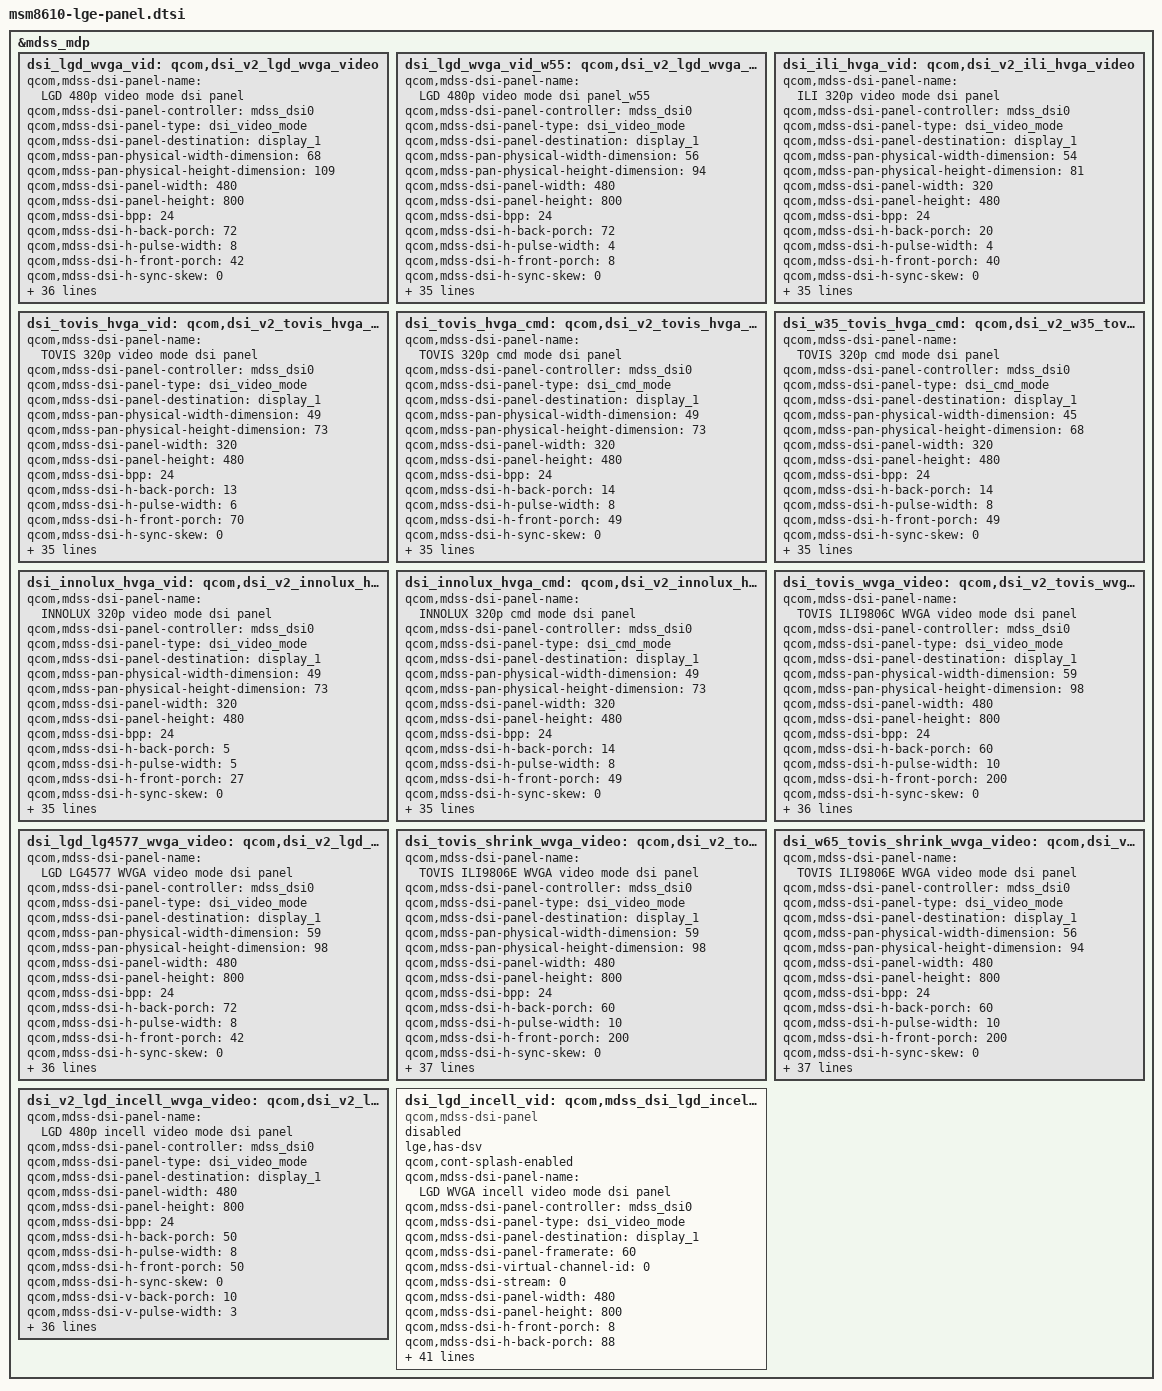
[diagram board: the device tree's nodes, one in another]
/* Copyright (c) 2012, Code Aurora Forum. All rights reserved.
 *
 * This program is free software; you can redistribute it and/or modify
 * it under the terms of the GNU General Public License version 2 and
 * only version 2 as published by the Free Software Foundation.
 *
 * This program is distributed in the hope that it will be useful,
 * but WITHOUT ANY WARRANTY; without even the implied warranty of
 * MERCHANTABILITY or FITNESS FOR A PARTICULAR PURPOSE.  See the
 * GNU General Public License for more details.
 */

&mdss_mdp {
	/* W6DS display - LGD 4573B */
	dsi_lgd_wvga_vid: qcom,dsi_v2_lgd_wvga_video {
		qcom,mdss-dsi-panel-name = "LGD 480p video mode dsi panel";
		qcom,mdss-dsi-panel-controller = <&mdss_dsi0>;
		qcom,mdss-dsi-panel-type = "dsi_video_mode";
		qcom,mdss-dsi-panel-destination = "display_1";
    qcom,mdss-pan-physical-width-dimension = <68>;
    qcom,mdss-pan-physical-height-dimension = <109>;
		qcom,mdss-dsi-panel-width = <480>;
		qcom,mdss-dsi-panel-height = <800>;
		qcom,mdss-dsi-bpp = <24>;
		qcom,mdss-dsi-h-back-porch = <72>;
		qcom,mdss-dsi-h-pulse-width = <8>;
		qcom,mdss-dsi-h-front-porch = <42>;
		qcom,mdss-dsi-h-sync-skew = <0>;
		qcom,mdss-dsi-v-back-porch = <16>;
		qcom,mdss-dsi-v-pulse-width = <10>;
		qcom,mdss-dsi-v-front-porch = <8>;
		qcom,mdss-dsi-underflow-color = <0xff>;
		qcom,mdss-dsi-bl-min-level = <1>;
		qcom,mdss-dsi-bl-max-level = <255>;
		qcom,mdss-dsi-bl-pmic-control-type = "bl_ctrl_wled";
		qcom,mdss-dsi-h-sync-pulse = <1>;
		qcom,mdss-dsi-hfp-power-mode;
		qcom,mdss-dsi-hbp-power-mode;
		qcom,mdss-dsi-hsa-power-mode;
		qcom,mdss-dsi-bllp-eof-power-mode;
		qcom,mdss-dsi-bllp-power-mode;
		qcom,mdss-dsi-traffic-mode = "non_burst_sync_event";
		qcom,mdss-dsi-virtual-channel-id = <0>;
		qcom,mdss-dsi-color-order = "rgb_swap_rgb";
		qcom,mdss-dsi-lane-0-state;
		qcom,mdss-dsi-lane-1-state;
		qcom,mdss-dsi-lane-map = "lane_map_3012";
		qcom,mdss-dsi-t-clk-pre = <0x2D>;
		qcom,mdss-dsi-t-clk-post = <0x19>;
		qcom,mdss-dsi-stream = <0>;
		qcom,mdss-dsi-mdp-trigger = "none";
		qcom,mdss-dsi-dma-trigger = "trigger_sw";
		qcom,mdss-dsi-panel-framerate = <60>;
		qcom,mdss-dsi-panel-timings = [A9 8A 16 00 91 93 1A 8C 11 03 04 00];
		qcom,mdss-dsi-on-command-state = "dsi_lp_mode";
		qcom,mdss-dsi-off-command-state = "dsi_lp_mode";
		qcom,mdss-dsi-reset-sequence = <1 1>, <0 1>, <1 10>;
		qcom,mdss-dsi-on-command = [
				05 01 00 00 00 00 01
				  20
				15 01 00 00 00 00 02
				  36 03
				15 01 00 00 00 00 02
				  3A 70
				39 01 00 00 00 00 04
				  B1 06 43 0A
				39 01 00 00 00 00 03
				  B2 20 C8
				39 01 00 00 00 00 02
				  B3 00
				39 01 00 00 00 00 02
				  B4 04
				39 01 00 00 00 00 06
				  B5 40 10 10 00 00
				39 01 00 00 00 00 07
				  B6 03 3F 02 40 3F E8
				39 01 00 00 00 00 06
				  C3 07 0A 0A 0A 02
				39 01 00 00 00 00 07
				  C4 12 24 18 18 01 49
				39 01 00 00 00 00 02
				  C5 74
				39 01 00 00 00 00 04
				  C6 41 63 03
				39 01 00 00 00 00 0A
				  D0 00 55 67 02 01 00 31 02 02
				39 01 00 00 00 00 0A
				  D1 00 55 67 02 01 00 31 02 02
				39 01 00 00 00 00 0A
				  D2 00 55 67 02 01 00 31 02 02
				39 01 00 00 00 00 0A
				  D3 00 55 67 02 01 00 31 02 02
				39 01 00 00 00 00 0A
				  D4 00 55 67 02 01 00 31 02 02
				39 01 00 00 00 00 0A
				  D5 00 55 67 02 01 00 31 02 02
				05 01 00 00 78 00 01
				  11
				05 01 00 00 28 00 01
				  29
		];
		qcom,mdss-dsi-off-command = [
				05 01 00 00 28 00 01
				  28
				05 01 00 00 3C 00 01
				  10
		];
	};
	dsi_lgd_wvga_vid_w55: qcom,dsi_v2_lgd_wvga_video_w55 {
		qcom,mdss-dsi-panel-name = "LGD 480p video mode dsi panel_w55";
		qcom,mdss-dsi-panel-controller = <&mdss_dsi0>;
		qcom,mdss-dsi-panel-type = "dsi_video_mode";
		qcom,mdss-dsi-panel-destination = "display_1";
		qcom,mdss-pan-physical-width-dimension = <56>;
		qcom,mdss-pan-physical-height-dimension = <94>;
		qcom,mdss-dsi-panel-width = <480>;
		qcom,mdss-dsi-panel-height = <800>;
		qcom,mdss-dsi-bpp = <24>;
		qcom,mdss-dsi-h-back-porch = <72>;
		qcom,mdss-dsi-h-pulse-width = <4>;
		qcom,mdss-dsi-h-front-porch = <8>;
		qcom,mdss-dsi-h-sync-skew = <0>;
		qcom,mdss-dsi-v-back-porch = <16>;
		qcom,mdss-dsi-v-pulse-width = <1>;
		qcom,mdss-dsi-v-front-porch = <8>;
		qcom,mdss-dsi-underflow-color = <0xff>;
		qcom,mdss-dsi-bl-min-level = <1>;
		qcom,mdss-dsi-bl-max-level = <255>;
		qcom,mdss-dsi-bl-pmic-control-type = "bl_ctrl_wled";
		qcom,mdss-dsi-h-sync-pulse = <1>;
		qcom,mdss-dsi-hfp-power-mode;
		qcom,mdss-dsi-hbp-power-mode;
		qcom,mdss-dsi-hsa-power-mode;
		qcom,mdss-dsi-bllp-eof-power-mode;
		qcom,mdss-dsi-bllp-power-mode;
		qcom,mdss-dsi-traffic-mode = "non_burst_sync_event";
		qcom,mdss-dsi-virtual-channel-id = <0>;
		qcom,mdss-dsi-color-order = "rgb_swap_rgb";
		qcom,mdss-dsi-lane-0-state;
		qcom,mdss-dsi-lane-1-state;
		qcom,mdss-dsi-lane-map = "lane_map_3012";
		qcom,mdss-dsi-t-clk-pre = <0x2D>;
		qcom,mdss-dsi-t-clk-post = <0x19>;
		qcom,mdss-dsi-stream = <0>;
		qcom,mdss-dsi-mdp-trigger = "none";
		qcom,mdss-dsi-dma-trigger = "trigger_sw";
		qcom,mdss-dsi-panel-framerate = <60>;
		qcom,mdss-dsi-panel-timings = [A5 89 15 00 8F 8F 18 8B 0F 03 04 00];
		qcom,mdss-dsi-on-command-state = "dsi_lp_mode";
		qcom,mdss-dsi-off-command-state = "dsi_lp_mode";
		qcom,mdss-dsi-on-command = [
				05 01 00 00 00 00 01
				  20
				15 01 00 00 00 00 02
				  36 00
				15 01 00 00 00 00 02
				  3A 70
				39 01 00 00 00 00 04
				  B1 06 43 0A
				39 01 00 00 00 00 03
				  B2 00 C8
				39 01 00 00 00 00 02
				  B3 02
				39 01 00 00 00 00 02
				  B4 00
				39 01 00 00 00 00 06
				  B5 40 10 10 00 00
				39 01 00 00 00 00 07
				  B6 0B 0F 02 40 10 E8
				39 01 00 00 00 00 06
				  C3 07 0A 0A 0A 02
				39 01 00 00 00 00 07
				  C4 12 24 18 18 02 49
				39 01 00 00 00 00 02
				  C5 69
				39 01 00 00 00 00 04
				  C6 41 63 03
				39 01 00 00 00 00 0A
				  D0 10 76 54 02 00 00 31 03 02
				39 01 00 00 00 00 0A
				  D1 10 76 54 02 00 00 31 03 02
				39 01 00 00 00 00 0A
				  D2 10 76 54 02 00 00 31 03 02
				39 01 00 00 00 00 0A
				  D3 10 76 54 02 00 00 31 03 02
				39 01 00 00 00 00 0A
				  D4 10 76 54 02 00 00 31 03 02
				39 01 00 00 00 00 0A
				  D5 10 76 54 02 00 00 31 03 02
				05 01 00 00 78 00 01
				  11
				05 01 00 00 28 00 01
				  29
		];
		qcom,mdss-dsi-off-command = [
				05 01 00 00 28 00 01
				  28
				05 01 00 00 0A 00 01
				  10
		];
	};
	dsi_ili_hvga_vid: qcom,dsi_v2_ili_hvga_video {
		qcom,mdss-dsi-panel-name = "ILI 320p video mode dsi panel";
		qcom,mdss-dsi-panel-controller = <&mdss_dsi0>;
		qcom,mdss-dsi-panel-type = "dsi_video_mode";
		qcom,mdss-dsi-panel-destination = "display_1";
		qcom,mdss-pan-physical-width-dimension = <54>;
		qcom,mdss-pan-physical-height-dimension = <81>;
		qcom,mdss-dsi-panel-width = <320>;
		qcom,mdss-dsi-panel-height = <480>;
		qcom,mdss-dsi-bpp = <24>;
		qcom,mdss-dsi-h-back-porch = <20>;
		qcom,mdss-dsi-h-pulse-width = <4>;
		qcom,mdss-dsi-h-front-porch = <40>;
		qcom,mdss-dsi-h-sync-skew = <0>;
		qcom,mdss-dsi-v-back-porch = <8>;
		qcom,mdss-dsi-v-pulse-width = <4>;
		qcom,mdss-dsi-v-front-porch = <8>;
		qcom,mdss-dsi-underflow-color = <0xff>;
		qcom,mdss-dsi-bl-min-level = <1>;
		qcom,mdss-dsi-bl-max-level = <255>;
		qcom,mdss-dsi-bl-pmic-control-type = "bl_ctrl_wled";
		qcom,mdss-dsi-h-sync-pulse = <0>;
		qcom,mdss-dsi-traffic-mode = "non_burst_sync_event";
		qcom,mdss-dsi-bllp-eof-power-mode;
		qcom,mdss-dsi-bllp-power-mode;
		qcom,mdss-dsi-te-dcs-command = <1>;
		qcom,mdss-dsi-te-v-sync-rd-ptr-irq-line = <0x2c>;
		qcom,mdss-dsi-te-v-sync-continues-lines = <0x3c>;
		qcom,mdss-dsi-virtual-channel-id = <0>;
		qcom,mdss-dsi-color-order = "rgb_swap_rgb";
		qcom,mdss-dsi-lane-0-state;
		qcom,mdss-dsi-lane-map = "lane_map_3012";
		qcom,mdss-dsi-t-clk-pre = <0x2C>;
		qcom,mdss-dsi-t-clk-post = <0x19>;
		qcom,mdss-dsi-stream = <0>;
		qcom,mdss-dsi-mdp-trigger = "trigger_te";
		qcom,mdss-dsi-dma-trigger = "trigger_sw";
		qcom,mdss-dsi-panel-framerate = <60>;
		qcom,mdss-dsi-panel-timings = [9F 87 10 00 8D 8E 14 89 0C 03 04 00];
		qcom,mdss-dsi-on-command-state = "dsi_lp_mode";
		qcom,mdss-dsi-off-command-state = "dsi_lp_mode";
		qcom,mdss-dsi-reset-sequence = <1 2>, <0 10>, <1 120>;
		qcom,mdss-dsi-on-command = [
				23 01 00 00 00 00 02
				  C1 41
				23 01 00 00 00 00 04
				  C0 0C 0C FF
				29 01 00 00 00 00 10
				  E0 00 11 13 05 10 06 3C
				  88 54 0A 0D 0B 30 36 0F
				29 01 00 00 00 00 10
				  E1 00 07 0D 04 12 04 29
				  44 42 09 0F 0A 2B 2D 0F
				29 01 00 00 00 00 04
				  C5 00 60 80
				39 01 00 00 00 00 03
				  B1 C0 15
				29 01 00 00 00 00 05
				  B5 0F 0F 0C 2A
				23 01 00 00 00 00 02
				  B4 20
				29 01 00 00 00 00 04
				  B6 82 42 3B
				23 01 00 00 00 00 02
				  E9 00
				39 01 00 00 00 00 06
				  F2 58 10 12 02 92
				39 01 00 00 00 00 05
				  F7 A9 51 2C 82
				15 01 00 00 00 00 02
				  3A 77
				05 01 00 00 00 00 02
				  21 00
				15 01 00 00 00 00 02
				  36 08
				05 01 00 00 78 00 01
				  11
				05 01 00 00 00 00 01
				  29
				05 01 00 00 50 00 01
				  2C
				];
		qcom,mdss-dsi-off-command = [
				05 01 00 00 32 00 01
				  28
				05 01 00 00 78 00 01
				  10
				];
	};
	dsi_tovis_hvga_vid: qcom,dsi_v2_tovis_hvga_video {
		qcom,mdss-dsi-panel-name = "TOVIS 320p video mode dsi panel";
		qcom,mdss-dsi-panel-controller = <&mdss_dsi0>;
		qcom,mdss-dsi-panel-type = "dsi_video_mode";
		qcom,mdss-dsi-panel-destination = "display_1";
		qcom,mdss-pan-physical-width-dimension = <49>;
		qcom,mdss-pan-physical-height-dimension = <73>;
		qcom,mdss-dsi-panel-width = <320>;
		qcom,mdss-dsi-panel-height = <480>;
		qcom,mdss-dsi-bpp = <24>;
		qcom,mdss-dsi-h-back-porch = <13>;
		qcom,mdss-dsi-h-pulse-width = <6>;
		qcom,mdss-dsi-h-front-porch = <70>;
		qcom,mdss-dsi-h-sync-skew = <0>;
		qcom,mdss-dsi-v-back-porch = <3>;
		qcom,mdss-dsi-v-pulse-width = <3>;
		qcom,mdss-dsi-v-front-porch = <3>;
		qcom,mdss-dsi-underflow-color = <0xff>;
		qcom,mdss-dsi-bl-min-level = <1>;
		qcom,mdss-dsi-bl-max-level = <255>;
		qcom,mdss-dsi-bl-pmic-control-type = "bl_ctrl_wled";
		qcom,mdss-dsi-h-sync-pulse = <0>;
		qcom,mdss-dsi-traffic-mode = "non_burst_sync_event";
		qcom,mdss-dsi-bllp-eof-power-mode;
		qcom,mdss-dsi-bllp-power-mode;
		qcom,mdss-dsi-te-dcs-command = <1>;
		qcom,mdss-dsi-te-v-sync-rd-ptr-irq-line = <0x2c>;
		qcom,mdss-dsi-te-v-sync-continues-lines = <0x3c>;
		qcom,mdss-dsi-virtual-channel-id = <0>;
		qcom,mdss-dsi-color-order = "rgb_swap_rgb";
		qcom,mdss-dsi-lane-0-state;
		qcom,mdss-dsi-lane-map = "lane_map_3012";
		qcom,mdss-dsi-t-clk-pre = <0x27>;
		qcom,mdss-dsi-t-clk-post = <0x20>;
		qcom,mdss-dsi-stream = <0>;
		qcom,mdss-dsi-mdp-trigger = "trigger_te";
		qcom,mdss-dsi-dma-trigger = "trigger_sw";
		qcom,mdss-dsi-panel-framerate = <60>;
		qcom,mdss-dsi-panel-timings = [45 16 0D 00 22 23 11 18 16 03 04 00];
		qcom,mdss-dsi-on-command-state = "dsi_lp_mode";
		qcom,mdss-dsi-off-command-state = "dsi_lp_mode";
		qcom,mdss-dsi-reset-sequence = <1 2>, <0 10>, <1 120>;
		qcom,mdss-dsi-on-command = [
				29 01 00 00 00 00 03
				  F8 21 05
				29 01 00 00 00 00 02
				  21 00
				39 01 00 00 00 00 02
				  36 88
				23 01 00 00 00 00 02
				  B4 00
				29 01 00 00 00 00 04
				  B6 82 42 3B
				29 01 00 00 00 00 03
				  C0 0A 0A
				23 01 00 00 00 00 02
				  C1 44
				23 01 00 00 00 00 02
				  C2 02
				29 01 00 00 00 00 05
				  C5 00 53 80 00
				29 01 00 00 00 00 10
				  E0 05 0A 0E 00 0C 03 2F 65 44 08 11 0D 25 2D 0F
				29 01 00 00 00 00 10
				  E1 00 0F 17 05 10 05 3C 43 4F 07 0F 0C 31 34 0F
				29 01 00 00 00 00 05
				  2A 00 00 01 3F
				29 01 00 00 00 00 05
				  2B 00 00 01 DF
				15 01 00 00 00 00 02
				  3A 77
				23 01 00 00 00 00 02
				  B7 C6
				39 01 00 00 00 00 03
				  B1 A0 11
				29 01 00 00 00 00 05
				  F7 A9 51 2C 82
				29 01 00 00 00 00 05
				  B5 02 02 0A 04
				15 01 00 00 00 00 02
				  51 FF
				15 01 00 00 00 00 02
				  53 24
				15 01 00 00 05 00 02
				  55 01
				15 01 00 00 00 00 02
				  CC 00
				05 01 00 00 78 00 01
				  11
				05 01 00 00 50 00 01
				  2C
				05 01 00 00 3C 00 01
				  29
				];
		qcom,mdss-dsi-off-command = [
				05 01 00 00 32 00 01
				  28
				05 01 00 00 78 00 01
				  10
				15 01 00 00 00 00 02
				  B7 08
				];
	};

	dsi_tovis_hvga_cmd: qcom,dsi_v2_tovis_hvga_cmd {
		qcom,mdss-dsi-panel-name = "TOVIS 320p cmd mode dsi panel";
		qcom,mdss-dsi-panel-controller = <&mdss_dsi0>;
		qcom,mdss-dsi-panel-type = "dsi_cmd_mode";
		qcom,mdss-dsi-panel-destination = "display_1";
		qcom,mdss-pan-physical-width-dimension = <49>;
		qcom,mdss-pan-physical-height-dimension = <73>;
		qcom,mdss-dsi-panel-width = <320>;
		qcom,mdss-dsi-panel-height = <480>;
		qcom,mdss-dsi-bpp = <24>;
		qcom,mdss-dsi-h-back-porch = <14>;
		qcom,mdss-dsi-h-pulse-width = <8>;
		qcom,mdss-dsi-h-front-porch = <49>;
		qcom,mdss-dsi-h-sync-skew = <0>;
		qcom,mdss-dsi-v-back-porch = <14>;
		qcom,mdss-dsi-v-pulse-width = <4>;
		qcom,mdss-dsi-v-front-porch = <14>;
		qcom,mdss-dsi-underflow-color = <0xff>;
		qcom,mdss-dsi-bl-min-level = <1>;
		qcom,mdss-dsi-bl-max-level = <255>;
		qcom,mdss-dsi-bl-pmic-control-type = "bl_ctrl_wled";
		qcom,mdss-dsi-h-sync-pulse = <0>;
		qcom,mdss-dsi-traffic-mode = "non_burst_sync_event";
		qcom,mdss-dsi-bllp-eof-power-mode;
		qcom,mdss-dsi-bllp-power-mode;
		qcom,mdss-dsi-te-dcs-command = <1>;
		qcom,mdss-dsi-te-v-sync-rd-ptr-irq-line = <0x2c>;
		qcom,mdss-dsi-te-v-sync-continues-lines = <0x3c>;
		qcom,mdss-dsi-virtual-channel-id = <0>;
		qcom,mdss-dsi-color-order = "rgb_swap_rgb";
		qcom,mdss-dsi-lane-0-state;
		qcom,mdss-dsi-lane-map = "lane_map_3012";
		qcom,mdss-dsi-t-clk-pre = <0x27>;
		qcom,mdss-dsi-t-clk-post = <0x20>;
		qcom,mdss-dsi-stream = <0>;
		qcom,mdss-dsi-mdp-trigger = "trigger_te";
		qcom,mdss-dsi-dma-trigger = "trigger_sw";
		qcom,mdss-dsi-panel-framerate = <60>;
		qcom,mdss-dsi-panel-timings = [4A 1A 12 00 25 26 16 1C 1C 03 04 00];
		qcom,mdss-dsi-on-command-state = "dsi_lp_mode";
		qcom,mdss-dsi-off-command-state = "dsi_lp_mode";
		qcom,mdss-dsi-reset-sequence = <1 2>, <0 10>, <1 120>;
		qcom,mdss-dsi-on-command = [
				29 01 00 00 00 00 03
				  F8 21 04
				29 01 00 00 00 00 02
				  21 00
				39 01 00 00 00 00 02
				  36 08
				23 01 00 00 00 00 02
				  B4 00
				29 01 00 00 00 00 04
				  B6 02 42 3B
				29 01 00 00 00 00 03
				  C0 0A 0A
				23 01 00 00 00 00 02
				  C1 44
				23 01 00 00 00 00 02
				  C2 02
				29 01 00 00 00 00 05
				  C5 00 42 80 00
				29 01 00 00 00 00 10
				  E0 05 08 0A 00 0C 03 2D 56 4A 09 11 0D 27 2D 0F
				29 01 00 00 00 00 10
				  E1 00 0D 15 03 0E 02 38 43 52 09 11 0E 34 36 0F
				29 01 00 00 00 00 05
				  2A 00 00 01 3F
				29 01 00 00 00 00 05
				  2B 00 00 01 DF
				15 01 00 00 00 00 02
				  3A 66
				23 01 00 00 00 00 02
				  B7 C6
				39 01 00 00 00 00 03
				  B1 A0 10
				29 01 00 00 00 00 05
				  F7 A9 51 2C 82
				29 01 00 00 00 00 05
				  B5 02 02 0A 04
				15 01 00 00 00 00 02
				  51 FF
				15 01 00 00 00 00 02
				  53 24
				15 01 00 00 05 00 02
				  55 01
				15 01 00 00 00 00 02
				  CC 01
				15 01 00 00 00 00 02
				  35 00
				29 01 00 00 00 00 03
				  44 00 00
				05 01 00 00 78 00 01
				  11
				05 01 00 00 50 00 01
				  2C
				05 01 00 00 3C 00 01
				  29
				];
		qcom,mdss-dsi-off-command = [
				05 01 00 00 32 00 01
				  28
				05 01 00 00 78 00 01
				  10
				15 01 00 00 00 00 02
				  B7 08
				];
	};
	
	//W35 Display
	dsi_w35_tovis_hvga_cmd: qcom,dsi_v2_w35_tovis_hvga_cmd {
		qcom,mdss-dsi-panel-name = "TOVIS 320p cmd mode dsi panel";
		qcom,mdss-dsi-panel-controller = <&mdss_dsi0>;
		qcom,mdss-dsi-panel-type = "dsi_cmd_mode";
		qcom,mdss-dsi-panel-destination = "display_1";
		qcom,mdss-pan-physical-width-dimension = <45>;
		qcom,mdss-pan-physical-height-dimension = <68>;
		qcom,mdss-dsi-panel-width = <320>;
		qcom,mdss-dsi-panel-height = <480>;
		qcom,mdss-dsi-bpp = <24>;
		qcom,mdss-dsi-h-back-porch = <14>;
		qcom,mdss-dsi-h-pulse-width = <8>;
		qcom,mdss-dsi-h-front-porch = <49>;
		qcom,mdss-dsi-h-sync-skew = <0>;
		qcom,mdss-dsi-v-back-porch = <14>;
		qcom,mdss-dsi-v-pulse-width = <4>;
		qcom,mdss-dsi-v-front-porch = <14>;
		qcom,mdss-dsi-underflow-color = <0xff>;
		qcom,mdss-dsi-bl-min-level = <1>;
		qcom,mdss-dsi-bl-max-level = <255>;
		qcom,mdss-dsi-bl-pmic-control-type = "bl_ctrl_wled";
		qcom,mdss-dsi-h-sync-pulse = <0>;
		qcom,mdss-dsi-traffic-mode = "non_burst_sync_event";
		qcom,mdss-dsi-bllp-eof-power-mode;
		qcom,mdss-dsi-bllp-power-mode;
		qcom,mdss-dsi-te-dcs-command = <1>;
		qcom,mdss-dsi-te-v-sync-rd-ptr-irq-line = <0x2c>;
		qcom,mdss-dsi-te-v-sync-continues-lines = <0x3c>;
		qcom,mdss-dsi-virtual-channel-id = <0>;
		qcom,mdss-dsi-color-order = "rgb_swap_rgb";
		qcom,mdss-dsi-lane-0-state;
		qcom,mdss-dsi-lane-map = "lane_map_3012";
		qcom,mdss-dsi-t-clk-pre = <0x27>;
		qcom,mdss-dsi-t-clk-post = <0x20>;
		qcom,mdss-dsi-stream = <0>;
		qcom,mdss-dsi-mdp-trigger = "trigger_te";
		qcom,mdss-dsi-dma-trigger = "trigger_sw";
		qcom,mdss-dsi-panel-framerate = <60>;
		qcom,mdss-dsi-panel-timings = [4A 1A 12 00 25 26 16 1C 1C 03 04 00];
		qcom,mdss-dsi-on-command-state = "dsi_lp_mode";
		qcom,mdss-dsi-off-command-state = "dsi_lp_mode";
		qcom,mdss-dsi-reset-sequence = <1 2>, <0 10>, <1 120>;
		qcom,mdss-dsi-on-command = [
				23 01 00 00 00 00 02	//power control 2
				  C1 41
				29 01 00 00 00 00 03	//power control 1
				  C0 15 15
				29 01 00 00 00 00 10	//positive gamma control
				  E0 00 09 12 0D 18 08 3F 89 52 0A 11 0F 22 25 0F
				29 01 00 00 00 00 10	//negative gamma control
				  E1 00 1B 20 00 0C 03 33 24 43 05 0B 04 2B 36 0F
				29 01 00 00 00 00 04	//Vcom control
				  C5 00 54 80
				39 01 00 00 00 00 02	//inferface mode control
				  B0 00
				39 01 00 00 00 00 02	//frame rate control
				  B1 A0
				23 01 00 00 00 00 02	//display inversion
				  B4 02
				29 01 00 00 00 00 04	//display control
				 B6 02 42 3B
				29 01 00 00 00 00 02	//set image function
				  E9 00
				29 01 00 00 00 00 05	//adjust control 3
				  F7 A9 51 2C 82
				15 01 00 00 00 00 02	//interface pixel format
				  3A 66
				39 01 00 00 00 00 04	//memory access
				  36 08	35 00		
				39 01 00 00 00 00 0C	//adjust control 2
				  F2 58 04 12 02 22 42 FF 0A 90 18 88  
				05 01 00 00 78 00 01	//sleep out
				  11
				05 01 00 00 3C 00 01	//display on
				  29
				05 01 00 00 50 00 01	//memory write
				  2C
				];
		qcom,mdss-dsi-off-command = [
				05 01 00 00 32 00 01
				  28
				05 01 00 00 78 00 01
				  10
				15 01 00 00 00 00 02
				  B7 08
				];
	};
	
	dsi_innolux_hvga_vid: qcom,dsi_v2_innolux_hvga_video {
		qcom,mdss-dsi-panel-name = "INNOLUX 320p video mode dsi panel";
		qcom,mdss-dsi-panel-controller = <&mdss_dsi0>;
		qcom,mdss-dsi-panel-type = "dsi_video_mode";
		qcom,mdss-dsi-panel-destination = "display_1";
		qcom,mdss-pan-physical-width-dimension = <49>;
		qcom,mdss-pan-physical-height-dimension = <73>;
		qcom,mdss-dsi-panel-width = <320>;
		qcom,mdss-dsi-panel-height = <480>;
		qcom,mdss-dsi-bpp = <24>;
		qcom,mdss-dsi-h-back-porch = <5>;
		qcom,mdss-dsi-h-pulse-width = <5>;
		qcom,mdss-dsi-h-front-porch = <27>;
		qcom,mdss-dsi-h-sync-skew = <0>;
		qcom,mdss-dsi-v-back-porch = <2>;
		qcom,mdss-dsi-v-pulse-width = <4>;
		qcom,mdss-dsi-v-front-porch = <2>;
		qcom,mdss-dsi-underflow-color = <0xff>;
		qcom,mdss-dsi-bl-min-level = <1>;
		qcom,mdss-dsi-bl-max-level = <255>;
		qcom,mdss-dsi-bl-pmic-control-type = "bl_ctrl_wled";
		qcom,mdss-dsi-h-sync-pulse = <0>;
		qcom,mdss-dsi-traffic-mode = "non_burst_sync_event";
		qcom,mdss-dsi-bllp-eof-power-mode;
		qcom,mdss-dsi-bllp-power-mode;
		qcom,mdss-dsi-te-dcs-command = <1>;
		qcom,mdss-dsi-te-v-sync-rd-ptr-irq-line = <0x2c>;
		qcom,mdss-dsi-te-v-sync-continues-lines = <0x3c>;
		qcom,mdss-dsi-virtual-channel-id = <0>;
		qcom,mdss-dsi-color-order = "rgb_swap_rgb";
		qcom,mdss-dsi-lane-0-state;
		qcom,mdss-dsi-lane-map = "lane_map_3012";
		qcom,mdss-dsi-t-clk-pre = <0x27>;
		qcom,mdss-dsi-t-clk-post = <0x20>;
		qcom,mdss-dsi-stream = <0>;
		qcom,mdss-dsi-mdp-trigger = "trigger_te";
		qcom,mdss-dsi-dma-trigger = "trigger_sw";
		qcom,mdss-dsi-panel-framerate = <60>;
		qcom,mdss-dsi-panel-timings = [45 16 0D 00 22 23 11 18 16 03 04 00];
		qcom,mdss-dsi-on-command-state = "dsi_lp_mode";
		qcom,mdss-dsi-off-command-state = "dsi_lp_mode";
		qcom,mdss-dsi-reset-sequence = <1 2>, <0 10>, <1 120>;
		qcom,mdss-dsi-on-command = [
				29 01 00 00 00 00 03
				  F8 21 05
				29 01 00 00 00 00 10
				  E0 00 10 14 03 0F 06 37 45 4A 02 0A 05 2F 3C 0F
				29 01 00 00 00 00 10
				  E1 00 15 19 02 11 07 3B 44 50 06 0D 0C 35 3A 0F
				15 01 00 00 00 00 02
				  51 FF
				15 01 00 00 00 00 02
				  53 24
				15 01 00 00 05 00 02
				  55 01
				15 01 00 00 00 00 02
				  CC 00
				29 01 00 00 00 00 03
				  C0 13 13
				23 01 00 00 00 00 02
				  C1 41
				23 01 00 00 00 00 02
				  C2 02
				39 01 00 00 00 00 02
				  36 88
				15 01 00 00 00 00 02
				  3A 77
				29 01 00 00 00 00 02
				  B0 00
				39 01 00 00 00 00 02
				  B1 A0
				23 01 00 00 00 00 02
				  B4 00
				29 01 00 00 00 00 03
				  B6 82 42
				29 01 00 00 00 00 02
				  E9 00
				29 01 00 00 00 00 05
				  F7 A9 51 2C 82
				29 01 00 00 00 00 07
				  D2 00 00 00 05 40 40
				05 01 00 00 96 00 01
				  11
				05 01 00 00 C8 00 01
				  29
				];
		qcom,mdss-dsi-off-command = [
				05 01 00 00 32 00 01
				  28
				05 01 00 00 78 00 01
				  10
				15 01 00 00 00 00 02
				  B7 08
				];
	};
	dsi_innolux_hvga_cmd: qcom,dsi_v2_innolux_hvga_cmd {
		qcom,mdss-dsi-panel-name = "INNOLUX 320p cmd mode dsi panel";
		qcom,mdss-dsi-panel-controller = <&mdss_dsi0>;
		qcom,mdss-dsi-panel-type = "dsi_cmd_mode";
		qcom,mdss-dsi-panel-destination = "display_1";
		qcom,mdss-pan-physical-width-dimension = <49>;
		qcom,mdss-pan-physical-height-dimension = <73>;
		qcom,mdss-dsi-panel-width = <320>;
		qcom,mdss-dsi-panel-height = <480>;
		qcom,mdss-dsi-bpp = <24>;
		qcom,mdss-dsi-h-back-porch = <14>;
		qcom,mdss-dsi-h-pulse-width = <8>;
		qcom,mdss-dsi-h-front-porch = <49>;
		qcom,mdss-dsi-h-sync-skew = <0>;
		qcom,mdss-dsi-v-back-porch = <14>;
		qcom,mdss-dsi-v-pulse-width = <4>;
		qcom,mdss-dsi-v-front-porch = <14>;
		qcom,mdss-dsi-underflow-color = <0xff>;
		qcom,mdss-dsi-bl-min-level = <1>;
		qcom,mdss-dsi-bl-max-level = <255>;
		qcom,mdss-dsi-bl-pmic-control-type = "bl_ctrl_wled";
		qcom,mdss-dsi-h-sync-pulse = <0>;
		qcom,mdss-dsi-traffic-mode = "non_burst_sync_event";
		qcom,mdss-dsi-bllp-eof-power-mode;
		qcom,mdss-dsi-bllp-power-mode;
		qcom,mdss-dsi-te-dcs-command = <1>;
		qcom,mdss-dsi-te-v-sync-rd-ptr-irq-line = <0x2c>;
		qcom,mdss-dsi-te-v-sync-continues-lines = <0x3c>;
		qcom,mdss-dsi-virtual-channel-id = <0>;
		qcom,mdss-dsi-color-order = "rgb_swap_rgb";
		qcom,mdss-dsi-lane-0-state;
		qcom,mdss-dsi-lane-map = "lane_map_3012";
		qcom,mdss-dsi-t-clk-pre = <0x27>;
		qcom,mdss-dsi-t-clk-post = <0x20>;
		qcom,mdss-dsi-stream = <0>;
		qcom,mdss-dsi-mdp-trigger = "trigger_te";
		qcom,mdss-dsi-dma-trigger = "trigger_sw";
		qcom,mdss-dsi-panel-framerate = <60>;
		qcom,mdss-dsi-panel-timings = [4A 1A 12 00 25 26 16 1C 1C 03 04 00];
		qcom,mdss-dsi-on-command-state = "dsi_lp_mode";
		qcom,mdss-dsi-off-command-state = "dsi_lp_mode";
		qcom,mdss-dsi-reset-sequence = <1 2>, <0 10>, <1 120>;
		qcom,mdss-dsi-on-command = [
				15 01 00 00 00 00 02
				  51 FF
				15 01 00 00 00 00 02
				  53 24
				15 01 00 00 05 00 02
				  55 01
				15 01 00 00 00 00 02
				  CC 00
				29 01 00 00 00 00 03
				  C0 13 13
				23 01 00 00 00 00 02
				  C1 41
				39 01 00 00 00 00 02
				  36 08
				29 01 00 00 00 00 02
				  21 00
				15 01 00 00 00 00 02
				  3A 66
				29 01 00 00 00 00 02
				  B0 00
				39 01 00 00 00 00 03
				  B1 A0 10
				23 01 00 00 00 00 02
				  B4 00
				29 01 00 00 00 00 04
				  B6 02 42 3B
				29 01 00 00 00 00 05
				  F7 A9 51 2C 82
				29 01 00 00 00 00 03
				  F8 21 06
				29 01 00 00 00 00 10
				  E0 00 09 0F 03 0D 05 33 36 4C 0E 1B 0F 24 23 0F
				29 01 00 00 00 00 10
				  E1 00 14 1C 00 0F 07 37 44 53 09 0D 0C 35 37 0F
				29 01 00 00 00 00 11
				  E2 A0 A0 A0 A0 A0 A0 A0 A0 A0 A0 A0 A0 A0 A0 A0 C0
				29 01 00 00 00 00 41
				  E3 00 00 00 00 00 00 00 00 00 00 00 00 00 00 00 00
				  00 00 00 00 00 00 00 00 00 00 00 00 00 00 00 00
				  00 00 00 00 00 00 00 00 00 00 00 00 00 00 00 00
				  00 00 00 00 00 00 00 00 00 00 00 00 00 00 00 30
				15 01 00 00 00 00 02
				  35 00
				05 01 00 00 96 00 01
				  11
				05 01 00 00 C8 00 01
				  29
				];
		qcom,mdss-dsi-off-command = [
				05 01 00 00 32 00 01
				  28
				05 01 00 00 78 00 01
				  10
				15 01 00 00 00 00 02
				  B7 08
				];
	};
	/* W5DS display - TOVIS */
	dsi_tovis_wvga_video: qcom,dsi_v2_tovis_wvga_video {
		qcom,mdss-dsi-panel-name = "TOVIS ILI9806C WVGA video mode dsi panel";
		qcom,mdss-dsi-panel-controller = <&mdss_dsi0>;
		qcom,mdss-dsi-panel-type = "dsi_video_mode";
		qcom,mdss-dsi-panel-destination = "display_1";
        qcom,mdss-pan-physical-width-dimension = <59>;
        qcom,mdss-pan-physical-height-dimension = <98>;
		qcom,mdss-dsi-panel-width = <480>;
		qcom,mdss-dsi-panel-height = <800>;
		qcom,mdss-dsi-bpp = <24>;
		qcom,mdss-dsi-h-back-porch = <60>;
		qcom,mdss-dsi-h-pulse-width = <10>;
		qcom,mdss-dsi-h-front-porch = <200>;
		qcom,mdss-dsi-h-sync-skew = <0>;
		qcom,mdss-dsi-v-back-porch = <17>;
		qcom,mdss-dsi-v-pulse-width = <2>;
		qcom,mdss-dsi-v-front-porch = <20>;
		qcom,mdss-dsi-underflow-color = <0xff>;
		qcom,mdss-dsi-bl-min-level = <1>;
		qcom,mdss-dsi-bl-max-level = <255>;
        qcom,mdss-dsi-bl-pmic-control-type = "bl_ctrl_wled";
        qcom,mdss-dsi-h-sync-pulse = <0>;
		qcom,mdss-dsi-traffic-mode = "non_burst_sync_event";
		qcom,mdss-dsi-bllp-eof-power-mode;
		qcom,mdss-dsi-bllp-power-mode;
        qcom,mdss-dsi-te-dcs-command = <1>;
		qcom,mdss-dsi-te-v-sync-rd-ptr-irq-line = <0x2c>;
		qcom,mdss-dsi-te-v-sync-continues-lines = <0x3c>;
        qcom,mdss-dsi-virtual-channel-id = <0>;
		qcom,mdss-dsi-color-order = "rgb_swap_rgb";
		qcom,mdss-dsi-lane-0-state;
		qcom,mdss-dsi-lane-1-state;
		qcom,mdss-dsi-lane-map = "lane_map_3012";
		qcom,mdss-dsi-t-clk-pre = <0x17>;
		qcom,mdss-dsi-t-clk-post = <0x04>;
		qcom,mdss-dsi-stream = <0>;
		qcom,mdss-dsi-mdp-trigger = "none";
		qcom,mdss-dsi-dma-trigger = "trigger_sw";
		qcom,mdss-dsi-panel-framerate = <60>;
		qcom,mdss-dsi-panel-timings = [A6 89 15 00 90 8F 18 8B 0F 03 04 00];
		qcom,mdss-dsi-on-command-state = "dsi_lp_mode";
		qcom,mdss-dsi-off-command-state = "dsi_lp_mode";
		qcom,mdss-dsi-reset-sequence = <1 1>, <0 1>, <1 10>;
		qcom,mdss-dsi-on-command = [
				39 01 00 00 00 00 04
					FF FF 98 16
				15 01 00 00 00 00 02
					BA 60
				39 01 00 00 00 00 18 /* Set GOA Timing */
					BC 01 0D 61 FF 01 01 0B 0E 6A 13 0E 6A 01 01 00 00 55 50 00 0C 0D 43 0B
				39 01 00 00 00 00 09 /* Set GOA Timing */
					BD 01 23 45 67 01 23 45 67
				39 01 00 00 00 00 12 /* Set GOA Timing */
					BE 02 22 11 AA BB 66 00 22 22 22 22 22 22 22 22 22 22
				39 01 00 00 00 00 09 /* Set Source Timing */
					D5 02 07 0F 06 CB A5 01 04
				15 01 00 00 00 00 02 /* Set Inversion Control */
					B4 00
				39 01 00 00 00 00 03 /* Set POWER1 */
					ED 7F 0F
				15 01 00 00 00 00 02 /* Set POWER2 */
					F3 70
				39 01 00 00 00 00 04 /* Set POWER3 */
					C0 AB 0B 44
				39 01 00 00 00 00 05 /* Set POWER4 */
					C1 17 78 78 20
				15 01 00 00 00 00 02 /* Set Vcom */
					C7 50
				39 01 00 00 00 00 11 /* Set GAMMA Positive */
					E0 00 0F 12 0A 03 09 08 06 04 09 0C 03 07 18 10 00
				39 01 00 00 00 00 11 /* Set GAMMA Positive */
					E1 00 0F 11 0A 03 08 09 06 04 09 0D 03 08 18 10 00
				15 01 00 00 00 00 02 /* Set RESOLUTION */
					F7 8A
				15 01 00 00 00 00 02 /* Set Scan DIRECTION */
					36 03
				05 01 00 00 78 00 01 /* Sleep out */
					11
				05 01 00 00 0A 00 01 /* Display On */
					29
					];
		qcom,mdss-dsi-off-command = [
				05 01 00 00 32 00 01
				  28
				05 01 00 00 78 00 01
				  10
				];
	};
	dsi_lgd_lg4577_wvga_video: qcom,dsi_v2_lgd_lg4577_wvga_video {
		qcom,mdss-dsi-panel-name = "LGD LG4577 WVGA video mode dsi panel";
		qcom,mdss-dsi-panel-controller = <&mdss_dsi0>;
		qcom,mdss-dsi-panel-type = "dsi_video_mode";
		qcom,mdss-dsi-panel-destination = "display_1";
        qcom,mdss-pan-physical-width-dimension = <59>;
        qcom,mdss-pan-physical-height-dimension = <98>;
		qcom,mdss-dsi-panel-width = <480>;
		qcom,mdss-dsi-panel-height = <800>;
		qcom,mdss-dsi-bpp = <24>;
		qcom,mdss-dsi-h-back-porch = <72>;
		qcom,mdss-dsi-h-pulse-width = <8>;
		qcom,mdss-dsi-h-front-porch = <42>;
		qcom,mdss-dsi-h-sync-skew = <0>;
		qcom,mdss-dsi-v-back-porch = <16>;
		qcom,mdss-dsi-v-pulse-width = <10>;
		qcom,mdss-dsi-v-front-porch = <8>;
		qcom,mdss-dsi-underflow-color = <0xff>;
		qcom,mdss-dsi-bl-min-level = <1>;
		qcom,mdss-dsi-bl-max-level = <255>;
        qcom,mdss-dsi-bl-pmic-control-type = "bl_ctrl_wled";
        qcom,mdss-dsi-h-sync-pulse = <0>;
		qcom,mdss-dsi-traffic-mode = "non_burst_sync_event";
		qcom,mdss-dsi-bllp-eof-power-mode;
		qcom,mdss-dsi-bllp-power-mode;
        qcom,mdss-dsi-te-dcs-command = <1>;
		qcom,mdss-dsi-te-v-sync-rd-ptr-irq-line = <0x2c>;
		qcom,mdss-dsi-te-v-sync-continues-lines = <0x3c>;
        qcom,mdss-dsi-virtual-channel-id = <0>;
		qcom,mdss-dsi-color-order = "rgb_swap_rgb";
		qcom,mdss-dsi-lane-0-state;
		qcom,mdss-dsi-lane-1-state;
		qcom,mdss-dsi-lane-map = "lane_map_3012";
		qcom,mdss-dsi-t-clk-pre = <0x2D>;
		qcom,mdss-dsi-t-clk-post = <0x19>;
		qcom,mdss-dsi-stream = <0>;
		qcom,mdss-dsi-mdp-trigger = "none";
		qcom,mdss-dsi-dma-trigger = "trigger_sw";
		qcom,mdss-dsi-panel-framerate = <60>;
		qcom,mdss-dsi-panel-timings = [5E 1D 15 00 2E 2B 1A 1F 25 03 04 00];
		qcom,mdss-dsi-on-command-state = "dsi_lp_mode";
		qcom,mdss-dsi-off-command-state = "dsi_lp_mode";
		qcom,mdss-dsi-reset-sequence = <1 1>, <0 1>, <1 10>;
		qcom,mdss-dsi-on-command = [
				15 01 00 00 00 00 02
				 	B0 AC
				05 01 00 00 00 00 01
				 	11
				39 01 00 00 00 00 06
				 	B1 40 10 10 00 10
				39 01 00 00 00 00 0A
				 	B2 08 00 38 01 40 10 10 00 10
				39 01 00 00 00 00 04
				 	B6 20 C7 04
				15 01 00 00 00 00 02
				 	C0 0A
				39 01 00 00 00 00 04
				 	C2 01 00 27
				39 01 00 00 00 00 08
				 	C3 33 00 12 A7 12 14 23
				39 01 00 00 00 00 07
				 	C4 A1 A9 81 83 81 38
				39 01 00 00 00 00 07
				  	C5 14 0F 0F 89 89 50
				15 01 00 00 00 00 02
				 	C6 65
				39 01 00 00 00 00 03
				 	C7 22 00
				39 01 00 00 00 00 0A
				 	D0 00 37 75 12 03 00 41 03 03
				39 01 00 00 00 00 0A
				 	D1 00 37 75 12 03 00 41 03 03
				39 01 00 00 00 00 0A
				 	D2 00 37 75 12 05 00 41 03 03
				39 01 00 00 00 00 0A
				 	D3 00 37 75 12 05 00 41 03 03
				39 01 00 00 00 00 0A
				 	D4 00 37 75 12 00 00 41 03 03
				39 01 00 00 00 00 0A
				 	D5 00 37 75 12 00 00 41 03 03
				05 01 00 00 78 00 01
				 	11
				05 01 00 00 28 00 01
				 	29
					];
		qcom,mdss-dsi-off-command = [
				05 01 00 00 32 00 01
				  28
				05 01 00 00 78 00 01
				  10
				];
	};
	/* W5DS Shrink display - TOVIS */
	dsi_tovis_shrink_wvga_video: qcom,dsi_v2_tovis_shrink_wvga_video {
		qcom,mdss-dsi-panel-name = "TOVIS ILI9806E WVGA video mode dsi panel";
		qcom,mdss-dsi-panel-controller = <&mdss_dsi0>;
		qcom,mdss-dsi-panel-type = "dsi_video_mode";
		qcom,mdss-dsi-panel-destination = "display_1";
        qcom,mdss-pan-physical-width-dimension = <59>;
        qcom,mdss-pan-physical-height-dimension = <98>;
		qcom,mdss-dsi-panel-width = <480>;
		qcom,mdss-dsi-panel-height = <800>;
		qcom,mdss-dsi-bpp = <24>;
		qcom,mdss-dsi-h-back-porch = <60>;
		qcom,mdss-dsi-h-pulse-width = <10>;
		qcom,mdss-dsi-h-front-porch = <200>;
		qcom,mdss-dsi-h-sync-skew = <0>;
		qcom,mdss-dsi-v-back-porch = <17>;
		qcom,mdss-dsi-v-pulse-width = <10>;
		qcom,mdss-dsi-v-front-porch = <20>;
		qcom,mdss-dsi-underflow-color = <0xff>;
		qcom,mdss-dsi-bl-min-level = <1>;
		qcom,mdss-dsi-bl-max-level = <255>;
        qcom,mdss-dsi-bl-pmic-control-type = "bl_ctrl_wled";
        qcom,mdss-dsi-h-sync-pulse = <0>;
		qcom,mdss-dsi-traffic-mode = "non_burst_sync_event";
		qcom,mdss-dsi-bllp-eof-power-mode;
		qcom,mdss-dsi-bllp-power-mode;
        qcom,mdss-dsi-te-dcs-command = <1>;
		qcom,mdss-dsi-te-v-sync-rd-ptr-irq-line = <0x2c>;
		qcom,mdss-dsi-te-v-sync-continues-lines = <0x3c>;
        qcom,mdss-dsi-virtual-channel-id = <0>;
		qcom,mdss-dsi-color-order = "rgb_swap_rgb";
		qcom,mdss-dsi-lane-0-state;
		qcom,mdss-dsi-lane-1-state;
		qcom,mdss-dsi-lane-map = "lane_map_3012";
		qcom,mdss-dsi-t-clk-pre = <0x17>;
		qcom,mdss-dsi-t-clk-post = <0x04>;
		qcom,mdss-dsi-stream = <0>;
		qcom,mdss-dsi-mdp-trigger = "none";
		qcom,mdss-dsi-dma-trigger = "trigger_sw";
		qcom,mdss-dsi-panel-framerate = <60>;
		qcom,mdss-dsi-panel-timings = [A6 89 15 00 90 8F 18 8B 0F 03 04 00];
		qcom,mdss-dsi-on-command-state = "dsi_lp_mode";
		qcom,mdss-dsi-off-command-state = "dsi_lp_mode";
		qcom,mdss-dsi-reset-sequence = <1 1>, <0 1>, <1 10>;
		qcom,mdss-dsi-on-command = [
				39 01 00 00 00 00 06 /* Set EXTC - Change to page 1 */
					FF FF 98 06 04 01	
				15 01 00 00 00 00 02 /* Set Resolution Control (480*800) */
					30 02 
				15 01 00 00 00 00 02 /* Column inversion */
					31 00
				15 01 00 00 00 00 02 /* Source Timing Adjust 1 (SDTI) */
					60 0F
				15 01 00 00 00 00 02 /* Source Timing Adjust 2 (CRTI) */
					61 00
				15 01 00 00 00 00 02 /* Source Timing Adjust 3 (EQTI) */
					62 07 
				15 01 00 00 00 00 02 /* Source Timing Adjust 4 (EQTI) */
					63 00 
				15 01 00 00 00 00 02 /* Power Control 1 */
					40 11
				15 01 00 00 00 00 02 /* Power Control 2 */
					41 27
				15 01 00 00 00 00 02 /* Power Control 3 */
					42 30
				15 01 00 00 00 00 02 /* Power Control 4*/
					43 85
				15 01 00 00 00 00 02 /* Power Control 5 */
					44 86
				15 01 00 00 00 00 02 /* Power Control 6 */
					45 9B
				15 01 00 00 00 00 02 /* Power Control 7 */
					46 44
				15 01 00 00 00 00 02 /* Power Control 8 */
					47 44
				15 01 00 00 00 00 02 /* Power Control 9 */
					50 78	
				15 01 00 00 00 00 02 /*  Power Control 10 */
					51 78
				15 01 00 00 00 00 02 /* VCOM Control 1~2 */
					52 00 
				15 01 00 00 00 00 02 /* VCOM Control 1~2 */
					53 47 
				15 01 00 00 00 00 02 /* VCOM Control 3~4 */
					54 00 
				15 01 00 00 00 00 02 /* VCOM Control 3~4 */
					55 47 
				15 01 00 00 00 00 02 /* VCOM Control 5 */
					56 00 
				15 01 00 00 00 00 02 /* Positive Gamma Control (01h~16h) */
					A0 00
				15 01 00 00 00 00 02 
					A1 00 
				15 01 00 00 00 00 02 
					A2 0C 
				15 01 00 00 00 00 02 
					A3 06 
				15 01 00 00 00 00 02 
					A4 03
				15 01 00 00 00 00 02 
					A5 07
				15 01 00 00 00 00 02 
					A6 06
				15 01 00 00 00 00 02 
					A7 04
				15 01 00 00 00 00 02 
					A8 09
				15 01 00 00 00 00 02 
					A9 0C
				15 01 00 00 00 00 02 
					AA 15
				15 01 00 00 00 00 02 
					AB 08
				15 01 00 00 00 00 02 
					AC 11 
				15 01 00 00 00 00 02 
					AD 13
				15 01 00 00 00 00 02 
					AE 0A
				15 01 00 00 00 00 02 
					AF 00
				15 01 00 00 00 00 02 /* Negative Gamma Control (01h~16h) */
					C0 00
				15 01 00 00 00 00 02 
					C1 00
				15 01 00 00 00 00 02 
					C2 08
				15 01 00 00 00 00 02 
					C3 08
				15 01 00 00 00 00 02 
					C4 01
				15 01 00 00 00 00 02 
					C5 07
				15 01 00 00 00 00 02 
					C6 05
				15 01 00 00 00 00 02 
					C7 04
				15 01 00 00 00 00 02 
					C8 09
				15 01 00 00 00 00 02 
					C9 0C
				15 01 00 00 00 00 02 
					CA 16
				15 01 00 00 00 00 02 
					CB 08
				15 01 00 00 00 00 02 
					CC 11
				15 01 00 00 00 00 02 
					CD 21
				15 01 00 00 00 00 02 
					CE 0F
				15 01 00 00 00 00 02 
					CF 00 
				39 01 00 00 00 00 06 /* Set EXTC - Change to page 7 */
					FF FF 98 06 04 07	
				15 01 00 00 00 00 02 /* VGL_REG Enable */
					18 1D	
				15 01 00 00 00 00 02 /* VREG1/2OUT Enable */
					17 12	
				15 01 00 00 00 00 02 
					02 CC 
				15 01 00 00 00 00 02 
					E1 79
				39 01 00 00 00 00 06 /* Set EXTC - Change to page 6 */
					FF FF 98 06 04 06	
				15 01 00 00 00 00 02 
					00 A0	
				15 01 00 00 00 00 02 
					01 05
				15 01 00 00 00 00 02 
					02 00
				15 01 00 00 00 00 02 
					03 00
				15 01 00 00 00 00 02 
					04 01
				15 01 00 00 00 00 02 
					05 01
				15 01 00 00 00 00 02 
					06 88
				15 01 00 00 00 00 02 
					07 04
				15 01 00 00 00 00 02 
					08 01
				15 01 00 00 00 00 02 
					09 90
				15 01 00 00 00 00 02 
					0A 04
				15 01 00 00 00 00 02 
					0B 01
				15 01 00 00 00 00 02 
					0C 01
				15 01 00 00 00 00 02 
					0D 01
				15 01 00 00 00 00 02 
					0E 00
				15 01 00 00 00 00 02 
					0F 00
				15 01 00 00 00 00 02 
					10 55
				15 01 00 00 00 00 02 
					11 50	
				15 01 00 00 00 00 02 
					12 01
				15 01 00 00 00 00 02 
					13 85 
				15 01 00 00 00 00 02 
					14 85 
				15 01 00 00 00 00 02 
					15 C0 
				15 01 00 00 00 00 02 
					16 0B
				15 01 00 00 00 00 02 
					17 00
				15 01 00 00 00 00 02 
					18 00
				15 01 00 00 00 00 02 
					19 00
				15 01 00 00 00 00 02 
					1A 00
				15 01 00 00 00 00 02 
					1B 00
				15 01 00 00 00 00 02 
					1C 00
				15 01 00 00 00 00 02 
					1D 00
				15 01 00 00 00 00 02 
					20 01
				15 01 00 00 00 00 02 
					21 23
				15 01 00 00 00 00 02 
					22 45
				15 01 00 00 00 00 02 
					23 67
				15 01 00 00 00 00 02 
					24 01
				15 01 00 00 00 00 02 
					25 23
				15 01 00 00 00 00 02 
					26 45
				15 01 00 00 00 00 02 
					27 67
				15 01 00 00 00 00 02 
					30 02
				15 01 00 00 00 00 02 
					31 22
				15 01 00 00 00 00 02 
					32 11
				15 01 00 00 00 00 02 
					33 AA
				15 01 00 00 00 00 02 
					34 BB
				15 01 00 00 00 00 02 
					35 66
				15 01 00 00 00 00 02 
					36 00
				15 01 00 00 00 00 02 
					37 22
				15 01 00 00 00 00 02 
					38 22
				15 01 00 00 00 00 02 
					39 22
				15 01 00 00 00 00 02 
					3A 22
				15 01 00 00 00 00 02 
					3B 22
				15 01 00 00 00 00 02 
					3C 22
				15 01 00 00 00 00 02 
					3D 22
				15 01 00 00 00 00 02 
					3E 22
				15 01 00 00 00 00 02 
					3F 22
				15 01 00 00 00 00 02 
					40 22
				15 01 00 00 00 00 02 /* GOUT_VGLO Control */ 
					53 1A
				39 01 00 00 00 00 06 /* Set EXTC - Change to page 2 */
					FF FF 98 06 04 02	
				15 01 00 00 00 00 02 /* Digital gamma enable */
					40 01
				15 01 00 00 00 00 02 /* Digital gamma control 1 */
					00 00
				15 01 00 00 00 00 02 /* Digital gamma control 1 */
					01 00
				15 01 00 00 00 00 02 /* Digital gamma control 1 */
					02 02
				15 01 00 00 00 00 02 /* Digital gamma control 1 */
					03 02
				15 01 00 00 00 00 02 /* Digital gamma control 1 */
					04 03
				15 01 00 00 00 00 02 /* Digital gamma control 1 */
					05 03
				15 01 00 00 00 00 02 /* Digital gamma control 1 */
					06 04
				15 01 00 00 00 00 02 /* Digital gamma control 1 */
					07 04
				15 01 00 00 00 00 02 /* Digital gamma control 1 */
					08 05
				15 01 00 00 00 00 02 /* Digital gamma control 1 */
					09 05
				15 01 00 00 00 00 02 /* Digital gamma control 1 */
					0A 05
				15 01 00 00 00 00 02 /* Digital gamma control 1 */
					0B 05
				15 01 00 00 00 00 02 /* Digital gamma control 1 */
					0C 05
				15 01 00 00 00 00 02 /* Digital gamma control 1 */
					0D 05
				15 01 00 00 00 00 02 /* Digital gamma control 1 */
					0E 05
				15 01 00 00 00 00 02 /* Digital gamma control 1 */
					0F 05
				15 01 00 00 00 00 02 /* Digital gamma control 1 */
					10 05
				15 01 00 00 00 00 02 /* Digital gamma control 1 */
					11 05
				15 01 00 00 00 00 02 /* Digital gamma control 1 */
					12 05
				15 01 00 00 00 00 02 /* Digital gamma control 1 */
					13 05
				15 01 00 00 00 00 02 /* Digital gamma control 1 */
					14 05
				15 01 00 00 00 00 02 /* Digital gamma control 1 */
					15 05
				15 01 00 00 00 00 02 /* Digital gamma control 1 */
					16 05
				15 01 00 00 00 00 02 /* Digital gamma control 1 */
					17 05
				15 01 00 00 00 00 02 /* Digital gamma control 1 */
					18 05
				15 01 00 00 00 00 02 /* Digital gamma control 1 */
					19 05
				15 01 00 00 00 00 02 /* Digital gamma control 1 */
					1A 05
				15 01 00 00 00 00 02 /* Digital gamma control 1 */
					1B 06
				15 01 00 00 00 00 02 /* Digital gamma control 1 */
					1C 06
				15 01 00 00 00 00 02 /* Digital gamma control 1 */
					1D 06
				15 01 00 00 00 00 02 /* Digital gamma control 1 */
					1E 06
				15 01 00 00 00 00 02 /* Digital gamma control 1 */
					1F 06
				15 01 00 00 00 00 02 /* Digital gamma control 1 */
					20 06
				15 01 00 00 00 00 02 /* Digital gamma control 1 */
					21 06
				15 01 00 00 00 00 02 /* Digital gamma control 1 */
					22 06
				15 01 00 00 00 00 02 /* Digital gamma control 1 */
					23 06
				15 01 00 00 00 00 02 /* Digital gamma control 1 */
					24 06
				15 01 00 00 00 00 02 /* Digital gamma control 1 */
					25 06
				15 01 00 00 00 00 02 /* Digital gamma control 1 */
					26 06
				15 01 00 00 00 00 02 /* Digital gamma control 1 */
					27 06
				15 01 00 00 00 00 02 /* Digital gamma control 1 */
					28 06
				15 01 00 00 00 00 02 /* Digital gamma control 1 */
					29 06
				15 01 00 00 00 00 02 /* Digital gamma control 1 */
					2A 06
				15 01 00 00 00 00 02 /* Digital gamma control 1 */
					2B 06
				15 01 00 00 00 00 02 /* Digital gamma control 1 */
					2C 05
				15 01 00 00 00 00 02 /* Digital gamma control 1 */
					2D 05
				15 01 00 00 00 00 02 /* Digital gamma control 1 */
					2E 05
				15 01 00 00 00 00 02 /* Digital gamma control 1 */
					2F 05
				15 01 00 00 00 00 02 /* Digital gamma control 1 */
					30 04
				15 01 00 00 00 00 02 /* Digital gamma control 1 */
					31 04
				15 01 00 00 00 00 02 /* Digital gamma control 1 */
					32 04
				15 01 00 00 00 00 02 /* Digital gamma control 1 */
					33 04
				15 01 00 00 00 00 02 /* Digital gamma control 1 */
					34 04
				15 01 00 00 00 00 02 /* Digital gamma control 1 */
					35 04
				15 01 00 00 00 00 02 /* Digital gamma control 1 */
					36 04
				15 01 00 00 00 00 02 /* Digital gamma control 1 */
					37 04
				15 01 00 00 00 00 02 /* Digital gamma control 1 */
					38 03
				15 01 00 00 00 00 02 /* Digital gamma control 1 */
					39 03
				15 01 00 00 00 00 02 /* Digital gamma control 1 */
					3A 03
				15 01 00 00 00 00 02 /* Digital gamma control 1 */
					3B 03
				15 01 00 00 00 00 02 /* Digital gamma control 1 */
					3C 01
				15 01 00 00 00 00 02 /* Digital gamma control 1 */
					3D 01
				15 01 00 00 00 00 02 /* Digital gamma control 1 */
					3E 00
				15 01 00 00 00 00 02 /* Digital gamma control 1 */
					3F 00
				39 01 00 00 00 00 06 /* Set EXTC - Change to page 3 */
					FF FF 98 06 04 03	
				15 01 00 00 00 00 02 /* Digital gamma control 1 */
					00 00
				15 01 00 00 00 00 02 /* Digital gamma control 1 */
					01 00
				15 01 00 00 00 00 02 /* Digital gamma control 1 */
					02 00
				15 01 00 00 00 00 02 /* Digital gamma control 1 */
					03 00
				15 01 00 00 00 00 02 /* Digital gamma control 1 */
					04 00
				15 01 00 00 00 00 02 /* Digital gamma control 1 */
					05 00
				15 01 00 00 00 00 02 /* Digital gamma control 1 */
					06 00
				15 01 00 00 00 00 02 /* Digital gamma control 1 */
					07 00
				15 01 00 00 00 00 02 /* Digital gamma control 1 */
					08 00
				15 01 00 00 00 00 02 /* Digital gamma control 1 */
					09 00
				15 01 00 00 00 00 02 /* Digital gamma control 1 */
					0A 00
				15 01 00 00 00 00 02 /* Digital gamma control 1 */
					0B 00
				15 01 00 00 00 00 02 /* Digital gamma control 1 */
					0C 00
				15 01 00 00 00 00 02 /* Digital gamma control 1 */
					0D 00
				15 01 00 00 00 00 02 /* Digital gamma control 1 */
					0E 00
				15 01 00 00 00 00 02 /* Digital gamma control 1 */
					0F 00
				15 01 00 00 00 00 02 /* Digital gamma control 1 */
					10 02
				15 01 00 00 00 00 02 /* Digital gamma control 1 */
					11 02
				15 01 00 00 00 00 02 /* Digital gamma control 1 */
					12 02
				15 01 00 00 00 00 02 /* Digital gamma control 1 */
					13 02
				15 01 00 00 00 00 02 /* Digital gamma control 1 */
					14 02
				15 01 00 00 00 00 02 /* Digital gamma control 1 */
					15 02
				15 01 00 00 00 00 02 /* Digital gamma control 1 */
					16 02
				15 01 00 00 00 00 02 /* Digital gamma control 1 */
					17 02
				15 01 00 00 00 00 02 /* Digital gamma control 1 */
					18 02
				15 01 00 00 00 00 02 /* Digital gamma control 1 */
					19 02
				15 01 00 00 00 00 02 /* Digital gamma control 1 */
					1A 02
				15 01 00 00 00 00 02 /* Digital gamma control 1 */
					1B 02
				15 01 00 00 00 00 02 /* Digital gamma control 1 */
					1C 02
				15 01 00 00 00 00 02 /* Digital gamma control 1 */
					1D 02
				15 01 00 00 00 00 02 /* Digital gamma control 1 */
					1E 02
				15 01 00 00 00 00 02 /* Digital gamma control 1 */
					1F 02
				15 01 00 00 00 00 02 /* Digital gamma control 1 */
					20 02
				15 01 00 00 00 00 02 /* Digital gamma control 1 */
					21 02
				15 01 00 00 00 00 02 /* Digital gamma control 1 */
					22 02
				15 01 00 00 00 00 02 /* Digital gamma control 1 */
					23 02
				15 01 00 00 00 00 02 /* Digital gamma control 1 */
					24 02
				15 01 00 00 00 00 02 /* Digital gamma control 1 */
					25 02
				15 01 00 00 00 00 02 /* Digital gamma control 1 */
					26 02
				15 01 00 00 00 00 02 /* Digital gamma control 1 */
					27 02
				15 01 00 00 00 00 02 /* Digital gamma control 1 */
					28 02
				15 01 00 00 00 00 02 /* Digital gamma control 1 */
					29 02
				15 01 00 00 00 00 02 /* Digital gamma control 1 */
					2A 04
				15 01 00 00 00 00 02 /* Digital gamma control 1 */
					2B 04
				15 01 00 00 00 00 02 /* Digital gamma control 1 */
					2C 04
				15 01 00 00 00 00 02 /* Digital gamma control 1 */
					2D 04
				15 01 00 00 00 00 02 /* Digital gamma control 1 */
					2E 04
				15 01 00 00 00 00 02 /* Digital gamma control 1 */
					2F 04
				15 01 00 00 00 00 02 /* Digital gamma control 1 */
					30 04
				15 01 00 00 00 00 02 /* Digital gamma control 1 */
					31 04
				15 01 00 00 00 00 02 /* Digital gamma control 1 */
					32 04
				15 01 00 00 00 00 02 /* Digital gamma control 1 */
					33 04
				15 01 00 00 00 00 02 /* Digital gamma control 1 */
					34 04
				15 01 00 00 00 00 02 /* Digital gamma control 1 */
					35 04
				15 01 00 00 00 00 02 /* Digital gamma control 1 */
					36 04
				15 01 00 00 00 00 02 /* Digital gamma control 1 */
					37 04
				15 01 00 00 00 00 02 /* Digital gamma control 1 */
					38 04
				15 01 00 00 00 00 02 /* Digital gamma control 1 */
					39 04
				15 01 00 00 00 00 02 /* Digital gamma control 1 */
					3A 04
				15 01 00 00 00 00 02 /* Digital gamma control 1 */
					3B 04
				15 01 00 00 00 00 02 /* Digital gamma control 1 */
					3C 04
				15 01 00 00 00 00 02 /* Digital gamma control 1 */
					3D 04
				15 01 00 00 00 00 02 /* Digital gamma control 1 */
					3E 04
				15 01 00 00 00 00 02 /* Digital gamma control 1 */
					3F 04
				15 01 00 00 00 00 02 /* Digital gamma control 1 */
					40 06
				15 01 00 00 00 00 02 /* Digital gamma control 1 */
					41 06
				15 01 00 00 00 00 02 /* Digital gamma control 1 */
					42 06
				15 01 00 00 00 00 02 /* Digital gamma control 1 */
					43 06
				15 01 00 00 00 00 02 /* Digital gamma control 1 */
					44 06
				15 01 00 00 00 00 02 /* Digital gamma control 1 */
					45 06
				15 01 00 00 00 00 02 /* Digital gamma control 1 */
					46 06
				15 01 00 00 00 00 02 /* Digital gamma control 1 */
					47 06
				15 01 00 00 00 00 02 /* Digital gamma control 1 */
					48 06
				15 01 00 00 00 00 02 /* Digital gamma control 1 */
					49 06
				15 01 00 00 00 00 02 /* Digital gamma control 1 */
					4A 06
				15 01 00 00 00 00 02 /* Digital gamma control 1 */
					4B 06
				15 01 00 00 00 00 02 /* Digital gamma control 1 */
					4C 06
				15 01 00 00 00 00 02 /* Digital gamma control 1 */
					4D 06
				15 01 00 00 00 00 02 /* Digital gamma control 1 */
					4E 06
				15 01 00 00 00 00 02 /* Digital gamma control 1 */
					4F 06
				15 01 00 00 00 00 02 /* Digital gamma control 1 */
					50 06
				15 01 00 00 00 00 02 /* Digital gamma control 1 */
					51 06
				15 01 00 00 00 00 02 /* Digital gamma control 1 */
					52 06
				15 01 00 00 00 00 02 /* Digital gamma control 1 */
					53 06
				15 01 00 00 00 00 02 /* Digital gamma control 1 */
					54 06
				15 01 00 00 00 00 02 /* Digital gamma control 1 */
					55 06
				15 01 00 00 00 00 02 /* Digital gamma control 1 */
					56 06
				15 01 00 00 00 00 02 /* Digital gamma control 1 */
					57 06
				15 01 00 00 00 00 02 /* Digital gamma control 1 */
					58 06
				15 01 00 00 00 00 02 /* Digital gamma control 1 */
					59 06
				15 01 00 00 00 00 02 /* Digital gamma control 1 */
					5A 06
				15 01 00 00 00 00 02 /* Digital gamma control 1 */
					5B 06
				15 01 00 00 00 00 02 /* Digital gamma control 1 */
					5C 06
				15 01 00 00 00 00 02 /* Digital gamma control 1 */
					5D 07
				15 01 00 00 00 00 02 /* Digital gamma control 1 */
					5E 07
				15 01 00 00 00 00 02 /* Digital gamma control 1 */
					5F 07
				15 01 00 00 00 00 02 /* Digital gamma control 1 */
					60 07
				15 01 00 00 00 00 02 /* Digital gamma control 1 */
					61 09
				15 01 00 00 00 00 02 /* Digital gamma control 1 */
					62 09
				15 01 00 00 00 00 02 /* Digital gamma control 1 */
					63 09
				15 01 00 00 00 00 02 /* Digital gamma control 1 */
					64 09
				15 01 00 00 00 00 02 /* Digital gamma control 1 */
					65 09
				15 01 00 00 00 00 02 /* Digital gamma control 1 */
					66 09
				15 01 00 00 00 00 02 /* Digital gamma control 1 */
					67 09
				15 01 00 00 00 00 02 /* Digital gamma control 1 */
					68 09
				15 01 00 00 00 00 02 /* Digital gamma control 1 */
					69 09
				15 01 00 00 00 00 02 /* Digital gamma control 1 */
					6A 09
				15 01 00 00 00 00 02 /* Digital gamma control 1 */
					6B 09
				15 01 00 00 00 00 02 /* Digital gamma control 1 */
					6C 09
				15 01 00 00 00 00 02 /* Digital gamma control 1 */
					6D 09
				15 01 00 00 00 00 02 /* Digital gamma control 1 */
					6E 09
				15 01 00 00 00 00 02 /* Digital gamma control 1 */
					6F 09
				15 01 00 00 00 00 02 /* Digital gamma control 1 */
					70 09
				15 01 00 00 00 00 02 /* Digital gamma control 1 */
					71 09
				15 01 00 00 00 00 02 /* Digital gamma control 1 */
					72 09
				15 01 00 00 00 00 02 /* Digital gamma control 1 */
					73 09
				15 01 00 00 00 00 02 /* Digital gamma control 1 */
					74 09
				15 01 00 00 00 00 02 /* Digital gamma control 1 */
					75 09
				15 01 00 00 00 00 02 /* Digital gamma control 1 */
					76 09
				15 01 00 00 00 00 02 /* Digital gamma control 1 */
					77 09
				15 01 00 00 00 00 02 /* Digital gamma control 1 */
					78 09
				15 01 00 00 00 00 02 /* Digital gamma control 1 */
					79 09
				15 01 00 00 00 00 02 /* Digital gamma control 1 */
					7A 09
				15 01 00 00 00 00 02 /* Digital gamma control 1 */
					7B 09
				15 01 00 00 00 00 02 /* Digital gamma control 1 */
					7C 09
				15 01 00 00 00 00 02 /* Digital gamma control 1 */
					7D 09
				15 01 00 00 00 00 02 /* Digital gamma control 1 */
					7E 09
				15 01 00 00 00 00 02 /* Digital gamma control 1 */
					7F 09
				39 01 00 00 00 00 06 /* Set EXTC - Change to page 4 */
					FF FF 98 06 04 04	
				15 01 00 00 00 00 02 /* Digital gamma control 1 */
					00 09
				15 01 00 00 00 00 02 /* Digital gamma control 1 */
					01 09
				15 01 00 00 00 00 02 /* Digital gamma control 1 */
					02 09
				15 01 00 00 00 00 02 /* Digital gamma control 1 */
					03 09
				15 01 00 00 00 00 02 /* Digital gamma control 1 */
					04 08
				15 01 00 00 00 00 02 /* Digital gamma control 1 */
					05 08
				15 01 00 00 00 00 02 /* Digital gamma control 1 */
					06 08
				15 01 00 00 00 00 02 /* Digital gamma control 1 */
					07 08
				15 01 00 00 00 00 02 /* Digital gamma control 1 */
					08 08
				15 01 00 00 00 00 02 /* Digital gamma control 1 */
					09 08
				15 01 00 00 00 00 02 /* Digital gamma control 1 */
					0A 08
				15 01 00 00 00 00 02 /* Digital gamma control 1 */
					0B 08
				15 01 00 00 00 00 02 /* Digital gamma control 1 */
					0C 08
				15 01 00 00 00 00 02 /* Digital gamma control 1 */
					0D 08
				15 01 00 00 00 00 02 /* Digital gamma control 1 */
					0E 08
				15 01 00 00 00 00 02 /* Digital gamma control 1 */
					0F 08
				15 01 00 00 00 00 02 /* Digital gamma control 1 */
					10 08
				15 01 00 00 00 00 02 /* Digital gamma control 1 */
					11 08
				15 01 00 00 00 00 02 /* Digital gamma control 1 */
					12 08
				15 01 00 00 00 00 02 /* Digital gamma control 1 */
					13 08
				15 01 00 00 00 00 02 /* Digital gamma control 1 */
					14 08
				15 01 00 00 00 00 02 /* Digital gamma control 1 */
					15 07
				15 01 00 00 00 00 02 /* Digital gamma control 1 */
					16 07
				15 01 00 00 00 00 02 /* Digital gamma control 1 */
					17 07
				15 01 00 00 00 00 02 /* Digital gamma control 1 */
					18 07
				15 01 00 00 00 00 02 /* Digital gamma control 1 */
					19 07
				15 01 00 00 00 00 02 /* Digital gamma control 1 */
					1A 07
				15 01 00 00 00 00 02 /* Digital gamma control 1 */
					1B 07
				15 01 00 00 00 00 02 /* Digital gamma control 1 */
					1C 07
				15 01 00 00 00 00 02 /* Digital gamma control 1 */
					1D 07
				15 01 00 00 00 00 02 /* Digital gamma control 1 */
					1E 07
				15 01 00 00 00 00 02 /* Digital gamma control 1 */
					1F 07
				15 01 00 00 00 00 02 /* Digital gamma control 1 */
					20 07
				15 01 00 00 00 00 02 /* Digital gamma control 1 */
					21 07
				15 01 00 00 00 00 02 /* Digital gamma control 1 */
					22 07
				15 01 00 00 00 00 02 /* Digital gamma control 1 */
					23 07
				15 01 00 00 00 00 02 /* Digital gamma control 1 */
					24 07
				15 01 00 00 00 00 02 /* Digital gamma control 1 */
					25 06
				15 01 00 00 00 00 02 /* Digital gamma control 1 */
					26 06
				15 01 00 00 00 00 02 /* Digital gamma control 1 */
					27 06
				15 01 00 00 00 00 02 /* Digital gamma control 1 */
					28 06
				15 01 00 00 00 00 02 /* Digital gamma control 1 */
					29 06
				15 01 00 00 00 00 02 /* Digital gamma control 1 */
					2A 06
				15 01 00 00 00 00 02 /* Digital gamma control 1 */
					2B 06
				15 01 00 00 00 00 02 /* Digital gamma control 1 */
					2C 06
				15 01 00 00 00 00 02 /* Digital gamma control 1 */
					2D 06
				15 01 00 00 00 00 02 /* Digital gamma control 1 */
					2E 06
				15 01 00 00 00 00 02 /* Digital gamma control 1 */
					2F 06
				15 01 00 00 00 00 02 /* Digital gamma control 1 */
					30 06
				15 01 00 00 00 00 02 /* Digital gamma control 1 */
					31 06
				15 01 00 00 00 00 02 /* Digital gamma control 1 */
					32 06
				15 01 00 00 00 00 02 /* Digital gamma control 1 */
					33 06
				15 01 00 00 00 00 02 /* Digital gamma control 1 */
					34 06
				15 01 00 00 00 00 02 /* Digital gamma control 1 */
					35 06
				15 01 00 00 00 00 02 /* Digital gamma control 1 */
					36 06
				15 01 00 00 00 00 02 /* Digital gamma control 1 */
					37 06
				15 01 00 00 00 00 02 /* Digital gamma control 1 */
					38 06
				15 01 00 00 00 00 02 /* Digital gamma control 1 */
					39 06
				15 01 00 00 00 00 02 /* Digital gamma control 1 */
					3A 06
				15 01 00 00 00 00 02 /* Digital gamma control 1 */
					3B 06
				15 01 00 00 00 00 02 /* Digital gamma control 1 */
					3C 06
				15 01 00 00 00 00 02 /* Digital gamma control 1 */
					3D 06
				15 01 00 00 00 00 02 /* Digital gamma control 1 */
					3E 06
				15 01 00 00 00 00 02 /* Digital gamma control 1 */
					3F 06
				15 01 00 00 00 00 02 /* Digital gamma control 1 */
					40 06
				15 01 00 00 00 00 02 /* Digital gamma control 1 */
					41 06
				15 01 00 00 00 00 02 /* Digital gamma control 1 */
					42 06
				15 01 00 00 00 00 02 /* Digital gamma control 1 */
					43 06
				15 01 00 00 00 00 02 /* Digital gamma control 1 */
					44 06
				15 01 00 00 00 00 02 /* Digital gamma control 1 */
					45 06
				15 01 00 00 00 00 02 /* Digital gamma control 1 */
					46 06
				15 01 00 00 00 00 02 /* Digital gamma control 1 */
					47 04
				15 01 00 00 00 00 02 /* Digital gamma control 1 */
					48 04
				15 01 00 00 00 00 02 /* Digital gamma control 1 */
					49 04
				15 01 00 00 00 00 02 /* Digital gamma control 1 */
					4A 04
				15 01 00 00 00 00 02 /* Digital gamma control 1 */
					4B 04
				15 01 00 00 00 00 02 /* Digital gamma control 1 */
					4C 04
				15 01 00 00 00 00 02 /* Digital gamma control 1 */
					4D 04
				15 01 00 00 00 00 02 /* Digital gamma control 1 */
					4E 04
				15 01 00 00 00 00 02 /* Digital gamma control 1 */
					4F 04
				15 01 00 00 00 00 02 /* Digital gamma control 1 */
					50 04
				15 01 00 00 00 00 02 /* Digital gamma control 1 */
					51 04
				15 01 00 00 00 00 02 /* Digital gamma control 1 */
					52 04
				15 01 00 00 00 00 02 /* Digital gamma control 1 */
					53 04
				15 01 00 00 00 00 02 /* Digital gamma control 1 */
					54 04
				15 01 00 00 00 00 02 /* Digital gamma control 1 */
					55 04
				15 01 00 00 00 00 02 /* Digital gamma control 1 */
					56 04
				15 01 00 00 00 00 02 /* Digital gamma control 1 */
					57 04
				15 01 00 00 00 00 02 /* Digital gamma control 1 */
					58 04
				15 01 00 00 00 00 02 /* Digital gamma control 1 */
					59 04
				15 01 00 00 00 00 02 /* Digital gamma control 1 */
					5A 04
				15 01 00 00 00 00 02 /* Digital gamma control 1 */
					5B 04
				15 01 00 00 00 00 02 /* Digital gamma control 1 */
					5C 04
				15 01 00 00 00 00 02 /* Digital gamma control 1 */
					5D 04
				15 01 00 00 00 00 02 /* Digital gamma control 1 */
					5E 04
				15 01 00 00 00 00 02 /* Digital gamma control 1 */
					5F 04
				15 01 00 00 00 00 02 /* Digital gamma control 1 */
					60 04
				15 01 00 00 00 00 02 /* Digital gamma control 1 */
					61 04
				15 01 00 00 00 00 02 /* Digital gamma control 1 */
					62 04
				15 01 00 00 00 00 02 /* Digital gamma control 1 */
					63 04
				15 01 00 00 00 00 02 /* Digital gamma control 1 */
					64 04
				15 01 00 00 00 00 02 /* Digital gamma control 1 */
					65 04
				15 01 00 00 00 00 02 /* Digital gamma control 1 */
					66 02
				15 01 00 00 00 00 02 /* Digital gamma control 1 */
					67 02
				15 01 00 00 00 00 02 /* Digital gamma control 1 */
					68 02
				15 01 00 00 00 00 02 /* Digital gamma control 1 */
					69 02
				15 01 00 00 00 00 02 /* Digital gamma control 1 */
					6A 02
				15 01 00 00 00 00 02 /* Digital gamma control 1 */
					6B 02
				15 01 00 00 00 00 02 /* Digital gamma control 1 */
					6C 02
				15 01 00 00 00 00 02 /* Digital gamma control 1 */
					6D 02
				15 01 00 00 00 00 02 /* Digital gamma control 1 */
					6E 02
				15 01 00 00 00 00 02 /* Digital gamma control 1 */
					6F 02
				15 01 00 00 00 00 02 /* Digital gamma control 1 */
					70 00
				15 01 00 00 00 00 02 /* Digital gamma control 1 */
					71 00
				15 01 00 00 00 00 02 /* Digital gamma control 1 */
					72 00
				15 01 00 00 00 00 02 /* Digital gamma control 1 */
					73 00
				15 01 00 00 00 00 02 /* Digital gamma control 1 */
					74 00
				15 01 00 00 00 00 02 /* Digital gamma control 1 */
					75 00
				15 01 00 00 00 00 02 /* Digital gamma control 1 */
					76 00
				15 01 00 00 00 00 02 /* Digital gamma control 1 */
					77 00
				15 01 00 00 00 00 02 /* Digital gamma control 1 */
					78 00
				15 01 00 00 00 00 02 /* Digital gamma control 1 */
					79 00
				15 01 00 00 00 00 02 /* Digital gamma control 1 */
					7A 00
				15 01 00 00 00 00 02 /* Digital gamma control 1 */
					7B 00
				15 01 00 00 00 00 02 /* Digital gamma control 1 */
					7C 00
				15 01 00 00 00 00 02 /* Digital gamma control 1 */
					7D 00
				15 01 00 00 00 00 02 /* Digital gamma control 1 */
					7E 00
				15 01 00 00 00 00 02 /* Digital gamma control 1 */
					7F 00
				39 01 00 00 00 00 06 /* Set EXTC - Change to page 5 */
					FF FF 98 06 04 05
				15 01 00 00 00 00 02 /* Digital gamma control 1 */
					22 2C
				39 01 00 00 00 00 06 /* Set EXTC - Change to page 0 */
					FF FF 98 06 04 00	
				15 01 00 00 00 00 02 /* Display Access Control */
					36 03
				15 01 00 00 00 00 02 /* White Display Brightness Value */
					51 FF
				15 01 00 00 00 00 02 /* White CTRL Display Value*/
					53 00
				15 01 00 00 00 00 02 /* Color Medium enhancement function Enable */
					55 B0
				05 01 00 00 78 00 01 /* Sleep out */
					11
				05 01 00 00 0A 00 01 /* Display On */
					29
		];
		qcom,mdss-dsi-off-command = [
				05 01 00 00 32 00 01
					28
				05 01 00 00 78 00 01
					10
		];
		qcom,off-cmds-dsi-state = "DSI_HS_MODE";
	};
	/* W65 Shrink display - TOVIS */
	dsi_w65_tovis_shrink_wvga_video: qcom,dsi_v2_w65_tovis_shrink_wvga_video {
		qcom,mdss-dsi-panel-name = "TOVIS ILI9806E WVGA video mode dsi panel";
		qcom,mdss-dsi-panel-controller = <&mdss_dsi0>;
		qcom,mdss-dsi-panel-type = "dsi_video_mode";
		qcom,mdss-dsi-panel-destination = "display_1";
              qcom,mdss-pan-physical-width-dimension = <56>;
              qcom,mdss-pan-physical-height-dimension = <94>;
		qcom,mdss-dsi-panel-width = <480>;
		qcom,mdss-dsi-panel-height = <800>;
		qcom,mdss-dsi-bpp = <24>;
		qcom,mdss-dsi-h-back-porch = <60>;
		qcom,mdss-dsi-h-pulse-width = <10>;
		qcom,mdss-dsi-h-front-porch = <200>;
		qcom,mdss-dsi-h-sync-skew = <0>;
		qcom,mdss-dsi-v-back-porch = <17>;
		qcom,mdss-dsi-v-pulse-width = <10>;
		qcom,mdss-dsi-v-front-porch = <20>;
		qcom,mdss-dsi-underflow-color = <0xff>;
		qcom,mdss-dsi-bl-min-level = <1>;
		qcom,mdss-dsi-bl-max-level = <255>;
        qcom,mdss-dsi-bl-pmic-control-type = "bl_ctrl_wled";
        qcom,mdss-dsi-h-sync-pulse = <0>;
		qcom,mdss-dsi-traffic-mode = "non_burst_sync_event";
		qcom,mdss-dsi-bllp-eof-power-mode;
		qcom,mdss-dsi-bllp-power-mode;
        qcom,mdss-dsi-te-dcs-command = <1>;
		qcom,mdss-dsi-te-v-sync-rd-ptr-irq-line = <0x2c>;
		qcom,mdss-dsi-te-v-sync-continues-lines = <0x3c>;
        qcom,mdss-dsi-virtual-channel-id = <0>;
		qcom,mdss-dsi-color-order = "rgb_swap_rgb";
		qcom,mdss-dsi-lane-0-state;
		qcom,mdss-dsi-lane-1-state;
		qcom,mdss-dsi-lane-map = "lane_map_3012";
		qcom,mdss-dsi-t-clk-pre = <0x17>;
		qcom,mdss-dsi-t-clk-post = <0x04>;
		qcom,mdss-dsi-stream = <0>;
		qcom,mdss-dsi-mdp-trigger = "none";
		qcom,mdss-dsi-dma-trigger = "trigger_sw";
		qcom,mdss-dsi-panel-framerate = <60>;
		qcom,mdss-dsi-panel-timings = [A6 89 15 00 90 8F 18 8B 0F 03 04 00];
		qcom,mdss-dsi-on-command-state = "dsi_lp_mode";
		qcom,mdss-dsi-off-command-state = "dsi_lp_mode";
		qcom,mdss-dsi-reset-sequence = <1 1>, <0 1>, <1 10>;
		qcom,mdss-dsi-on-command = [
				39 01 00 00 00 00 06 /* Set EXTC - Change to page 1 */
					FF FF 98 06 04 01	
				15 01 00 00 00 00 02 /* Set Resolution Control (480*800) */
					08 10 
				15 01 00 00 00 00 02 /* Column inversion */
					21 01
				15 01 00 00 00 00 02 /* Source Timing Adjust 1 (SDTI) */
					30 02
				15 01 00 00 00 00 02 /* Source Timing Adjust 2 (CRTI) */
					31 00
				15 01 00 00 00 00 02 /* Power Control 1 */
					40 11
				15 01 00 00 00 00 02 /* Power Control 2 */
					41 66
				15 01 00 00 00 00 02 /* Power Control 3 */
					42 02
				15 01 00 00 00 00 02 /* Power Control 4*/
					43 09
				15 01 00 00 00 00 02 /* Power Control 5 */
					44 06
				15 01 00 00 00 00 02 /* Power Control 9 */
					50 78	
				15 01 00 00 00 00 02 /*  Power Control 10 */
					51 78
				15 01 00 00 00 00 02 /* VCOM Control 1~2 */
					52 00 
				15 01 00 00 00 00 02 /* VCOM Control 1~2 */
					53 40 
				15 01 00 00 00 00 02 /* VCOM Control 3~4 */
					60 07 
				15 01 00 00 00 00 02 /* VCOM Control 3~4 */
					61 00 
				15 01 00 00 00 00 02 /* VCOM Control 5 */
					62 08 
				15 01 00 00 00 00 02 /* VCOM Control 5 */
					63 00
				15 01 00 00 00 00 02 /* Positive Gamma Control (01h~16h) */
					A0 05
				15 01 00 00 00 00 02 
					A1 0B 
				15 01 00 00 00 00 02 
					A2 16 
				15 01 00 00 00 00 02 
					A3 0F 
				15 01 00 00 00 00 02 
					A4 05
				15 01 00 00 00 00 02 
					A5 05
				15 01 00 00 00 00 02 
					A6 0a
				15 01 00 00 00 00 02 
					A7 08
				15 01 00 00 00 00 02 
					A8 05
				15 01 00 00 00 00 02 
					A9 0A
				15 01 00 00 00 00 02 
					AA 15
				15 01 00 00 00 00 02 
					AB 06
				15 01 00 00 00 00 02 
					AC 0D 
				15 01 00 00 00 00 02 
					AD 1B
				15 01 00 00 00 00 02 
					AE 12
				15 01 00 00 00 00 02 
					AF 00
				15 01 00 00 00 00 02 /* Negative Gamma Control (01h~16h) */
					C0 05
				15 01 00 00 00 00 02 
					C1 05
				15 01 00 00 00 00 02 
					C2 0B
				15 01 00 00 00 00 02 
					C3 16
				15 01 00 00 00 00 02 
					C4 05
				15 01 00 00 00 00 02 
					C5 05
				15 01 00 00 00 00 02 
					C6 0A
				15 01 00 00 00 00 02 
					C7 08
				15 01 00 00 00 00 02 
					C8 05
				15 01 00 00 00 00 02 
					C9 0A
				15 01 00 00 00 00 02 
					CA 15
				15 01 00 00 00 00 02 
					CB 06
				15 01 00 00 00 00 02 
					CC 0D
				15 01 00 00 00 00 02 
					CD 1B
				15 01 00 00 00 00 02 
					CE 12
				15 01 00 00 00 00 02 
					CF 00
				39 01 00 00 00 00 06 /* Set EXTC - Change to page 7 */
					FF FF 98 06 04 06	
				15 01 00 00 00 00 02 /* VGL_REG Enable */
					00 20	
				15 01 00 00 00 00 02 /* VREG1/2OUT Enable */
					01 04	
				15 01 00 00 00 00 02 
					02 00 
				15 01 00 00 00 00 02 
					03 08
				15 01 00 00 00 00 02 
					04 09
				15 01 00 00 00 00 02 
					05 09
				15 01 00 00 00 00 02 
					06 98
				15 01 00 00 00 00 02 
					07 02
				15 01 00 00 00 00 02 
					08 02
				15 01 00 00 00 00 02 
					09 80
				15 01 00 00 00 00 02 
					0A 00
				15 01 00 00 00 00 02 
					0B 00
				15 01 00 00 00 00 02 
					0C 09
				15 01 00 00 00 00 02 
					0D 09
				15 01 00 00 00 00 02 
					0E 00
				15 01 00 00 00 00 02 
					0F 00
				15 01 00 00 00 00 02 
					10 77
				15 01 00 00 00 00 02 
					11 F0	
				15 01 00 00 00 00 02 
					12 01
				15 01 00 00 00 00 02 
					13 00 
				15 01 00 00 00 00 02 
					14 00 
				15 01 00 00 00 00 02 
					15 43
				15 01 00 00 00 00 02 
					16 0B
				15 01 00 00 00 00 02 
					17 00
				15 01 00 00 00 00 02 
					18 00
				15 01 00 00 00 00 02 
					19 00
				15 01 00 00 00 00 02 
					1A 00
				15 01 00 00 00 00 02 
					1B 00
				15 01 00 00 00 00 02 
					1C 00
				15 01 00 00 00 00 02 
					1D 00
				15 01 00 00 00 00 02 
					20 01
				15 01 00 00 00 00 02 
					21 23
				15 01 00 00 00 00 02 
					22 45
				15 01 00 00 00 00 02 
					23 67
				15 01 00 00 00 00 02 
					24 01
				15 01 00 00 00 00 02 
					25 23
				15 01 00 00 00 00 02 
					26 45
				15 01 00 00 00 00 02 
					27 67
				15 01 00 00 00 00 02 
					30 13
				15 01 00 00 00 00 02 
					31 22
				15 01 00 00 00 00 02 
					32 22
				15 01 00 00 00 00 02 
					33 22
				15 01 00 00 00 00 02 
					34 22
				15 01 00 00 00 00 02 
					35 BB
				15 01 00 00 00 00 02 
					36 AA
				15 01 00 00 00 00 02 
					37 DD
				15 01 00 00 00 00 02 
					38 CC
				15 01 00 00 00 00 02 
					39 22
				15 01 00 00 00 00 02 
					3A 66
				15 01 00 00 00 00 02 
					3B 22
				15 01 00 00 00 00 02 
					3C 88
				15 01 00 00 00 00 02 
					3D 22
				15 01 00 00 00 00 02 
					3E 22
				15 01 00 00 00 00 02 
					3F 22
				15 01 00 00 00 00 02 
					40 22
				15 01 00 00 00 00 02 /* GOUT_VGLO Control */ 
					52 10
				39 01 00 00 00 00 06 /* Set EXTC - Change to page 2 */
					FF FF 98 06 04 07	
				15 01 00 00 00 00 02 /* Digital gamma enable */
					18 1D
				15 01 00 00 00 00 02 /* Digital gamma control 1 */
					02 77
				39 01 00 00 00 00 06 /* Set EXTC - Change to page 2 */
					FF FF 98 06 04 00	
				05 01 00 00 78 00 01 /* Sleep out */
					11
				05 01 00 00 0A 00 01 /* Display On */
					29
		];
		qcom,mdss-dsi-off-command = [
				05 01 00 00 32 00 01
					28
				05 01 00 00 78 00 01
					10
		];
		qcom,off-cmds-dsi-state = "DSI_HS_MODE";
	};
	/* W5 display - LGD Incell */
	dsi_v2_lgd_incell_wvga_video: qcom,dsi_v2_lgd_incell_wvga_video {
		qcom,mdss-dsi-panel-name = "LGD 480p incell video mode dsi panel";
		qcom,mdss-dsi-panel-controller = <&mdss_dsi0>;
		qcom,mdss-dsi-panel-type = "dsi_video_mode";
		qcom,mdss-dsi-panel-destination = "display_1";
		qcom,mdss-dsi-panel-width = <480>;
		qcom,mdss-dsi-panel-height = <800>;
		qcom,mdss-dsi-bpp = <24>;
		qcom,mdss-dsi-h-back-porch = <50>;
		qcom,mdss-dsi-h-pulse-width = <8>;
		qcom,mdss-dsi-h-front-porch = <50>;
		qcom,mdss-dsi-h-sync-skew = <0>;
		qcom,mdss-dsi-v-back-porch = <10>;
		qcom,mdss-dsi-v-pulse-width = <3>;
		qcom,mdss-dsi-v-front-porch = <950>;
		qcom,mdss-dsi-underflow-color = <0xff>;
		qcom,mdss-dsi-bl-min-level = <1>;
		qcom,mdss-dsi-bl-max-level = <4095>;
        qcom,mdss-dsi-bl-pmic-control-type = "bl_ctrl_wled";
        qcom,mdss-dsi-h-sync-pulse = <0>;
		qcom,mdss-dsi-traffic-mode = "non_burst_sync_event";
		qcom,mdss-dsi-bllp-eof-power-mode;
		//qcom,mdss-dsi-bllp-power-mode;
		qcom,mdss-dsi-hfp-power-mode = <1>;
		qcom,mdss-dsi-hsa-power-mode = <1>;
		qcom,mdss-dsi-hbp-power-mode = <1>;

        qcom,mdss-dsi-te-dcs-command = <1>;
		qcom,mdss-dsi-te-v-sync-rd-ptr-irq-line = <0x2c>;
		qcom,mdss-dsi-te-v-sync-continues-lines = <0x3c>;
        qcom,mdss-dsi-virtual-channel-id = <0>;
		qcom,mdss-dsi-color-order = "rgb_swap_rgb";
		qcom,mdss-dsi-lane-0-state;
		qcom,mdss-dsi-lane-1-state;
		qcom,mdss-dsi-lane-map = "lane_map_3012";
		qcom,mdss-dsi-t-clk-pre = <0x33>;
		qcom,mdss-dsi-t-clk-post = <0x19>;
		qcom,mdss-dsi-stream = <0>;
		qcom,mdss-dsi-mdp-trigger = "none";
		qcom,mdss-dsi-dma-trigger = "trigger_sw";
		qcom,mdss-dsi-panel-framerate = <60>;
		qcom,mdss-dsi-panel-timings = [D6 95 30 00 A4 9F 32 97 25 03 04 00];
		qcom,mdss-dsi-on-command-state = "dsi_lp_mode";
		qcom,mdss-dsi-off-command-state = "dsi_lp_mode";
		qcom,mdss-dsi-reset-sequence = <1 20>, <0 2>, <1 20>;
		qcom,mdss-dsi-on-command = [
				39 01 00 00 00 00 08
					B7 00 26 26 30 20 30 20
				39 01 00 00 00 00 07
					B6 50 0A 04 13 01 0A
				39 01 00 00 00 00 05
					B8 00 11 21 AB
				15 01 00 00 00 00 02
					B0 00
				15 01 00 00 00 00 02
					55 00
				39 01 00 00 00 00 0C
					/*C0 00 09 09 02 01 10 02 10 22 20 00*/ /* Touch Mux Disable */
					C0 61 09 09 02 01 10 02 10 22 20 00
				39 01 00 00 00 00 15
					C2 00 10 1B 20 20 23 29 31 3B 40 42 45 48 4C 55 58 65 70 90 A0 //Touch dtx lookup table
					/*C2 00 01 05 0A 0F 19 28 28 2D 32 32 3C 41 46 4B 50 5A 73 82 A0*/
				39 01 00 00 00 00 02
					D9 A0
				39 01 00 00 00 00 0B
					B5 03 18 01 12 06 02 02 02 02 48
				39 01 00 00 00 00 07
					B4 00 05 02 02 02 02
				15 01 00 00 00 00 03
					B2 00 D8
				39 01 00 00 00 00 05
					B1 C6 1E 0F 00
				39 01 00 00 00 00 07
					BA 00 28 28 28 28 28
				15 01 00 00 00 00 02
					36 14
				39 01 00 00 00 00 0A
					D0 55 46 33 33 00 00 66 11 02
				39 01 00 00 00 00 0A
					D1 55 46 33 33 00 00 66 11 02
				39 01 00 00 00 00 0A
					D2 55 46 33 33 00 00 66 11 02
				39 01 00 00 00 00 0A
					D3 55 46 33 33 00 00 66 11 02
				39 01 00 00 00 00 0A
					D4 55 46 33 33 00 00 66 11 02
				39 01 00 00 00 00 0A
					D5 55 46 33 33 00 00 66 11 02
				39 01 00 00 00 00 03
					D7 04 86
				05 01 00 00 64 00 02
					11 00
				05 01 00 00 64 00 02
					29 00
					];
		qcom,mdss-dsi-off-command = [
				05 01 00 00 32 00 02
					28 00
				05 01 00 00 78 00 02
					10 00
				];
	};

    /* L70P LGD Incell WVGA VIDEO*/
    dsi_lgd_incell_vid: qcom,mdss_dsi_lgd_incell_video{
	lge,has-dsv;
	compatible = "qcom,mdss-dsi-panel";
	status = "disable";
	qcom,cont-splash-enabled;
	qcom,mdss-dsi-panel-name = "LGD WVGA incell video mode dsi panel";
	qcom,mdss-dsi-panel-controller = <&mdss_dsi0>;
	qcom,mdss-dsi-panel-type = "dsi_video_mode";
	qcom,mdss-dsi-panel-destination = "display_1";
	qcom,mdss-dsi-panel-framerate = <60>;
	qcom,mdss-dsi-virtual-channel-id = <0>;
	qcom,mdss-dsi-stream = <0>;
	qcom,mdss-dsi-panel-width = <480>;
	qcom,mdss-dsi-panel-height = <800>;
	qcom,mdss-dsi-h-front-porch = <8>;
	qcom,mdss-dsi-h-back-porch = <88>;
	qcom,mdss-dsi-h-pulse-width = <8>;
	qcom,mdss-dsi-h-sync-skew = <0>;
	qcom,mdss-dsi-v-back-porch = <11>;
	qcom,mdss-dsi-v-front-porch = <980>;
	qcom,mdss-dsi-v-pulse-width = <4>;
	qcom,mdss-dsi-h-left-border = <0>;
	qcom,mdss-dsi-h-right-border = <0>;
	qcom,mdss-dsi-v-top-border = <0>;
	qcom,mdss-dsi-v-bottom-border = <0>;
	qcom,mdss-pan-physical-width-dimension = < 58 >;
	qcom,mdss-pan-physical-height-dimension = < 98 >;
	qcom,mdss-dsi-bpp = <24>;
	qcom,mdss-dsi-color-order = "rgb_swap_rgb";
	qcom,mdss-dsi-underflow-color = <0xff>;
	qcom,mdss-dsi-border-color = <0>;
	qcom,mdss-dsi-on-command = [
		39 01 00 00 00 00 08
		B7 00 1B 1B 1B 1B 1B 1B
		39 01 00 00 00 00 07
		B6 06 0A 34 23 41 0A
		39 01 00 00 00 00 05
		B8 00 42 12 F7

		15 01 00 00 00 00 02
		B0 00
		15 01 00 00 00 00 02
		55 00

		39 01 00 00 00 00 0B
		B5 03 A0 01 12 06 A0 A0 00 00 48
		39 01 00 00 00 00 07
		B4 00 0D 02 02 02 02

		15 01 00 00 00 00 02
		B2 00
		39 01 00 00 00 00 05
		B1 C6 1E 0F 00
		39 01 00 00 00 00 04
		B9 00 03 04
		15 01 00 00 00 00 02
		BB 25

		15 01 00 00 00 00 02
		36 00

		39 01 00 00 00 00 02
		D9 A0
		39 01 00 00 00 00 03
		F8 00 05
		39 01 00 00 00 00 03
		D7 00 A6
		39 01 00 00 00 00 03
		BD 00 23

		39 01 00 00 00 00 0A
		D0 02 37 74 14 00 00 31 03 03
		39 01 00 00 00 00 0A
		D1 02 37 74 14 00 00 31 03 03
		39 01 00 00 00 00 0A
		D2 02 37 74 14 00 00 31 03 03
		39 01 00 00 00 00 0A
		D3 02 37 74 14 00 00 31 03 03
		39 01 00 00 00 00 0A
		D4 02 37 74 14 00 00 31 03 03
		39 01 00 00 00 00 0A
		D5 02 37 74 14 00 00 31 03 03
		/* Disable Image Enhancer */
		/* Image Enhancer for Sharpen */
		39 01 00 00 00 00 04
		61 18 34 00
		/* Image Enhancer for Contrast */
		39 01 00 00 00 00 04
		62 3F 30 FF
		/* Prefer Color Compensation */
		39 01 00 00 00 00 02
		63 00
		39 01 00 00 00 00 1D
		64 81 7F 81 7F 7F 4D AD 85 6A
		99 9B 8C 7D 41 97 5F 64 22 6E
		19 44 69 B0 9C 7D 41 A5 5F
	];
	lge,display-on-cmds = [
		39 01 00 00 00 00 02
		FE 00
		05 01 00 00 78 00 02
		11 00
		05 01 00 00 00 00 02
		29 00
	];
	qcom,mdss-dsi-off-command = [
		05 01 00 00 64 00 02
		10 00
		39 01 00 00 00 00 02
		FE 05
	];
	qcom,mdss-dsi-on-command-state = "dsi_lp_mode";
	qcom,mdss-dsi-off-command-state = "dsi_hs_mode";
	qcom,mdss-dsi-h-sync-pulse = <0>;
	qcom,mdss-dsi-traffic-mode = "non_burst_sync_event";
	qcom,mdss-dsi-lane-map = "lane_map_3012";
	//qcom,mdss-dsi-hfp-power-mode;
	//qcom,mdss-dsi-hbp-power-mode;
	//qcom,mdss-dsi-hsa-power-mode;
	qcom,mdss-dsi-bllp-eof-power-mode;
	//qcom,mdss-dsi-bllp-power-mode;
	qcom,mdss-dsi-lane-0-state;
	qcom,mdss-dsi-lane-1-state;
	qcom,mdss-dsi-panel-timings = [D6 95 31 00 A4 9F 32 97 25 03 04 00];
	qcom,mdss-dsi-t-clk-pre = <0x33>;
	qcom,mdss-dsi-t-clk-post = <0x19>;
	qcom,mdss-dsi-bl-min-level = <1>;
	qcom,mdss-dsi-bl-max-level = <255>;
	qcom,mdss-dsi-dma-trigger = "trigger_sw";
	qcom,mdss-dsi-mdp-trigger = "none";
	qcom,mdss-dsi-bl-pmic-control-type = "bl_ctrl_wled";
	qcom,mdss-dsi-reset-sequence = <1 20>, <0 20>, <1 20>;
    };
};
